AUTOSAR XML (schema 314)
package /ComponentType
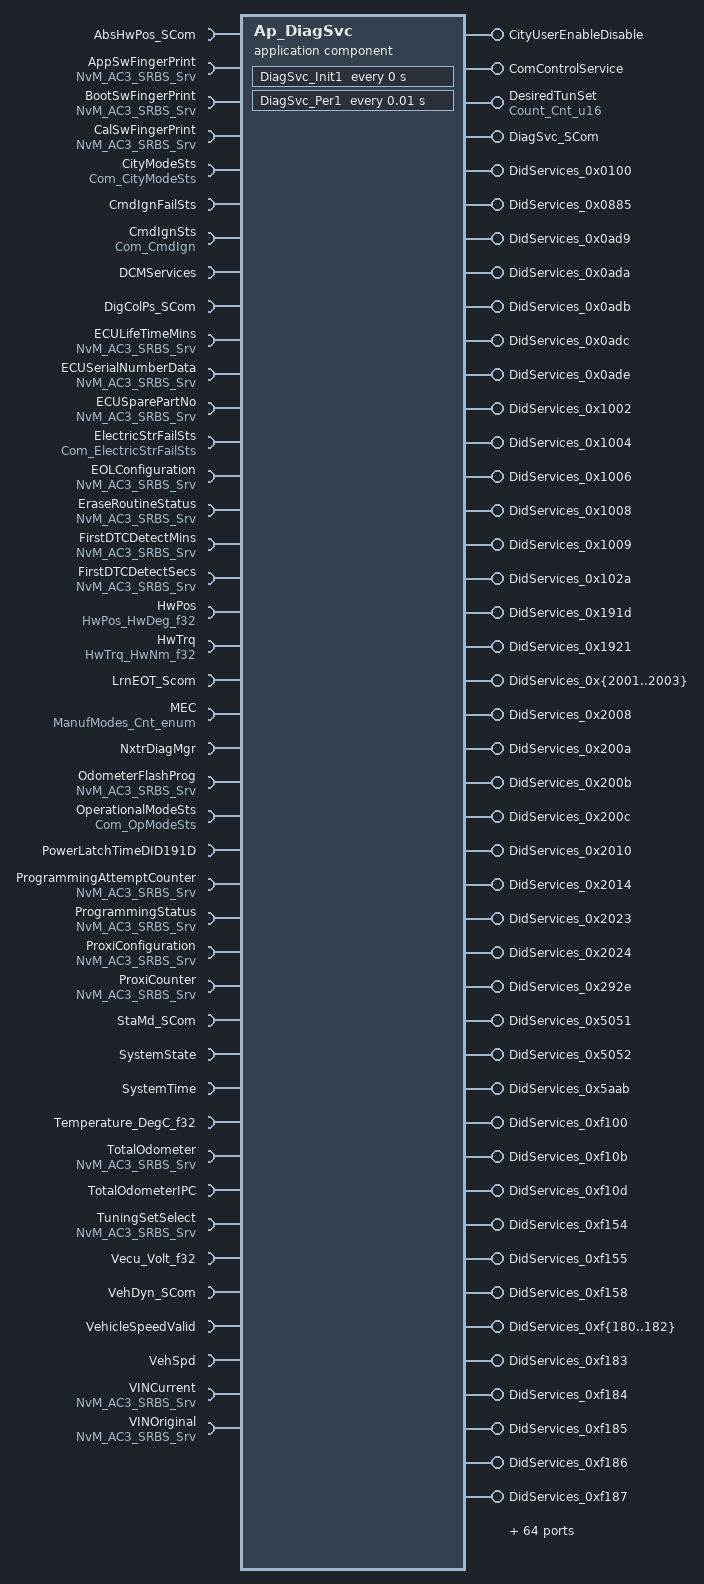
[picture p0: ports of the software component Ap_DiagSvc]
  application software component type Ap_DiagSvc
    118 x provide port:
      CityUserEnableDisable: unqueued-sender-com-spec{data-element=Cnt_enum, can-invalidate=false, init-value=D_CITYUSERENABLEDISABLE_ENUM}, provided-interface=CityUserEnableDisable
      ComControlService: server-com-spec{operation=CheckCondition, queue-length=1}, provided-interface=ComControlService
      DesiredTunSet: unqueued-sender-com-spec{data-element=Cnt_u16, can-invalidate=false, init-value=D_ZERO_CNT_U16}, provided-interface=Count_Cnt_u16
      DiagSvc_SCom: provided-com-specs=[{operation=GetTuningSet, queue-length=1}, {operation=SetTuningSet, queue-length=1}], provided-interface=DiagSvc_SCom
      DidServices_0x0100: provided-interface=DidServices_0x0100
        provided-com-specs:
          operation=ConditionCheckRead, queue-length=1
          operation=ConditionCheckWrite, queue-length=1
          operation=ReadData, queue-length=1
          operation=WriteData, queue-length=1
      DidServices_0x0885: provided-com-specs=[{operation=ConditionCheckRead, queue-length=1}, {operation=ReadData, queue-length=1}], provided-interface=DidServices_0x0885
      DidServices_0x0ad9: provided-com-specs=[{operation=ConditionCheckRead, queue-length=1}, {operation=ReadData, queue-length=1}], provided-interface=DidServices_0x0ad9
      DidServices_0x0ada: provided-com-specs=[{operation=ConditionCheckRead, queue-length=1}, {operation=ReadData, queue-length=1}], provided-interface=DidServices_0x0ada
      DidServices_0x0adb: provided-com-specs=[{operation=ConditionCheckRead, queue-length=1}, {operation=ReadData, queue-length=1}], provided-interface=DidServices_0x0adb
      DidServices_0x0adc: provided-com-specs=[{operation=ConditionCheckRead, queue-length=1}, {operation=ReadData, queue-length=1}], provided-interface=DidServices_0x0adc
      DidServices_0x0ade: provided-com-specs=[{operation=ConditionCheckRead, queue-length=1}, {operation=ReadData, queue-length=1}], provided-interface=DidServices_0x0ade
      DidServices_0x1002: provided-com-specs=[{operation=ConditionCheckRead, queue-length=1}, {operation=ReadData, queue-length=1}], provided-interface=DidServices_0x1002
      DidServices_0x1004: provided-com-specs=[{operation=ConditionCheckRead, queue-length=1}, {operation=ReadData, queue-length=1}], provided-interface=DidServices_0x1004
      DidServices_0x1006: provided-com-specs=[{operation=ConditionCheckRead, queue-length=1}, {operation=ReadData, queue-length=1}], provided-interface=DidServices_0x1006
      DidServices_0x1008: provided-com-specs=[{operation=ConditionCheckRead, queue-length=1}, {operation=ReadData, queue-length=1}], provided-interface=DidServices_0x1008
      DidServices_0x1009: provided-com-specs=[{operation=ConditionCheckRead, queue-length=1}, {operation=ReadData, queue-length=1}], provided-interface=DidServices_0x1009
      DidServices_0x102a: provided-com-specs=[{operation=ConditionCheckRead, queue-length=1}, {operation=ReadData, queue-length=1}], provided-interface=DidServices_0x102a
      DidServices_0x191d: provided-com-specs=[{operation=ConditionCheckRead, queue-length=1}, {operation=ReadData, queue-length=1}], provided-interface=DidServices_0x191d
      DidServices_0x1921: provided-com-specs=[{operation=ConditionCheckRead, queue-length=1}, {operation=ReadData, queue-length=1}], provided-interface=DidServices_0x1921
      DidServices_0x{2001..2003}: provided-com-specs=[{operation=ConditionCheckRead, queue-length=1}, {operation=ReadData, queue-length=1}], provided-interface=DidServices_0x{2001..2003}
      DidServices_0x2008: provided-com-specs=[{operation=ConditionCheckRead, queue-length=1}, {operation=ReadData, queue-length=1}], provided-interface=DidServices_0x2008
      DidServices_0x200a: provided-com-specs=[{operation=ConditionCheckRead, queue-length=1}, {operation=ReadData, queue-length=1}], provided-interface=DidServices_0x200a
      DidServices_0x200b: provided-com-specs=[{operation=ConditionCheckRead, queue-length=1}, {operation=ReadData, queue-length=1}], provided-interface=DidServices_0x200b
      DidServices_0x200c: provided-com-specs=[{operation=ConditionCheckRead, queue-length=1}, {operation=ReadData, queue-length=1}], provided-interface=DidServices_0x200c
      DidServices_0x2010: provided-com-specs=[{operation=ConditionCheckRead, queue-length=1}, {operation=ReadData, queue-length=1}], provided-interface=DidServices_0x2010
      DidServices_0x2014: provided-com-specs=[{operation=ConditionCheckRead, queue-length=1}, {operation=ReadData, queue-length=1}], provided-interface=DidServices_0x2014
      DidServices_0x2023: provided-com-specs=[{operation=ConditionCheckWrite, queue-length=1}, {operation=WriteData, queue-length=1}], provided-interface=DidServices_0x2023
      DidServices_0x2024: provided-com-specs=[{operation=ConditionCheckRead, queue-length=1}, {operation=ReadData, queue-length=1}], provided-interface=DidServices_0x2024
      DidServices_0x292e: provided-com-specs=[{operation=ConditionCheckRead, queue-length=1}, {operation=ReadData, queue-length=1}], provided-interface=DidServices_0x292e
      DidServices_0x5051: provided-interface=DidServices_0x5051
        provided-com-specs:
          operation=ResetToDefault, queue-length=1
          operation=ReturnControlToECU, queue-length=1
          operation=ShortTermAdjustment, queue-length=1
      DidServices_0x5052: provided-com-specs=[{operation=ReturnControlToECU, queue-length=1}, {operation=ShortTermAdjustment, queue-length=1}], provided-interface=DidServices_0x5052
      DidServices_0x5aab: provided-interface=DidServices_0x5aab
        provided-com-specs:
          operation=ResetToDefault, queue-length=1
          operation=ReturnControlToECU, queue-length=1
          operation=ShortTermAdjustment, queue-length=1
      DidServices_0xf100: provided-com-specs=[{operation=ConditionCheckRead, queue-length=1}, {operation=ReadData, queue-length=1}], provided-interface=DidServices_0xf100
      DidServices_0xf10b: provided-interface=DidServices_0xf10b
        provided-com-specs:
          operation=ConditionCheckRead, queue-length=1
          operation=ReadData, queue-length=1
          operation=ReadDataLength, queue-length=1
      DidServices_0xf10d: provided-com-specs=[{operation=ConditionCheckRead, queue-length=1}, {operation=ReadData, queue-length=1}], provided-interface=DidServices_0xf10d
      DidServices_0xf154: provided-com-specs=[{operation=ConditionCheckRead, queue-length=1}, {operation=ReadData, queue-length=1}], provided-interface=DidServices_0xf154
      DidServices_0xf155: provided-com-specs=[{operation=ConditionCheckRead, queue-length=1}, {operation=ReadData, queue-length=1}], provided-interface=DidServices_0xf155
      DidServices_0xf158: provided-com-specs=[{operation=ConditionCheckRead, queue-length=1}, {operation=ReadData, queue-length=1}], provided-interface=DidServices_0xf158
      DidServices_0xf{180..182}: provided-com-specs=[{operation=ConditionCheckRead, queue-length=1}, {operation=ReadData, queue-length=1}], provided-interface=DidServices_0xf{180..182}
      DidServices_0xf183: provided-interface=DidServices_0xf183
        provided-com-specs:
          operation=ConditionCheckRead, queue-length=1
          operation=ConditionCheckWrite, queue-length=1
          operation=ReadData, queue-length=1
          operation=WriteData, queue-length=1
      DidServices_0xf184: provided-interface=DidServices_0xf184
        provided-com-specs:
          operation=ConditionCheckRead, queue-length=1
          operation=ConditionCheckWrite, queue-length=1
          operation=ReadData, queue-length=1
          operation=WriteData, queue-length=1
      DidServices_0xf185: provided-interface=DidServices_0xf185
        provided-com-specs:
          operation=ConditionCheckRead, queue-length=1
          operation=ConditionCheckWrite, queue-length=1
          operation=ReadData, queue-length=1
          operation=WriteData, queue-length=1
      DidServices_0xf186: provided-com-specs=[{operation=ConditionCheckRead, queue-length=1}, {operation=ReadData, queue-length=1}], provided-interface=DidServices_0xf186
      DidServices_0xf187: provided-interface=DidServices_0xf187
        provided-com-specs:
          operation=ConditionCheckRead, queue-length=1
          operation=ConditionCheckWrite, queue-length=1
          operation=ReadData, queue-length=1
          operation=WriteData, queue-length=1
      DidServices_0xf188: provided-com-specs=[{operation=ConditionCheckRead, queue-length=1}, {operation=ReadData, queue-length=1}], provided-interface=DidServices_0xf188
      DidServices_0xf18c: provided-interface=DidServices_0xf18c
        provided-com-specs:
          operation=ConditionCheckRead, queue-length=1
          operation=ConditionCheckWrite, queue-length=1
          operation=ReadData, queue-length=1
          operation=WriteData, queue-length=1
      DidServices_0xf{191..195}: provided-com-specs=[{operation=ConditionCheckRead, queue-length=1}, {operation=ReadData, queue-length=1}], provided-interface=DidServices_0xf{191..195}
      DidServices_0xf1a0: provided-com-specs=[{operation=ConditionCheckRead, queue-length=1}, {operation=ReadData, queue-length=1}], provided-interface=DidServices_0xf1a0
      DidServices_0xf1a3: provided-com-specs=[{operation=ConditionCheckRead, queue-length=1}, {operation=ReadData, queue-length=1}], provided-interface=DidServices_0xf1a3
      DidServices_0xf1a4: provided-com-specs=[{operation=ConditionCheckRead, queue-length=1}, {operation=ReadData, queue-length=1}], provided-interface=DidServices_0xf1a4
      DidServices_0xfd01: provided-com-specs=[{operation=ConditionCheckRead, queue-length=1}, {operation=ReadData, queue-length=1}], provided-interface=DidServices_0xfd01
      DidServices_0xfd02: provided-interface=DidServices_0xfd02
        provided-com-specs:
          operation=ConditionCheckRead, queue-length=1
          operation=ConditionCheckWrite, queue-length=1
          operation=ReadData, queue-length=1
          operation=WriteData, queue-length=1
      DidServices_0xfd03: provided-interface=DidServices_0xfd03
        provided-com-specs:
          operation=ConditionCheckRead, queue-length=1
          operation=ConditionCheckWrite, queue-length=1
          operation=ReadData, queue-length=1
          operation=WriteData, queue-length=1
      DidServices_0xfd07: provided-interface=DidServices_0xfd07
        provided-com-specs:
          operation=ConditionCheckRead, queue-length=1
          operation=ConditionCheckWrite, queue-length=1
          operation=ReadData, queue-length=1
          operation=WriteData, queue-length=1
      DidServices_0xfd0d: provided-com-specs=[{operation=ReturnControlToECU, queue-length=1}, {operation=ShortTermAdjustment, queue-length=1}], provided-interface=DidServices_0xfd0d
      DidServices_0xfd0e: provided-com-specs=[{operation=ConditionCheckRead, queue-length=1}, {operation=ReadData, queue-length=1}], provided-interface=DidServices_0xfd0e
      DidServices_0xfd10: provided-com-specs=[{operation=ConditionCheckRead, queue-length=1}, {operation=ReadData, queue-length=1}], provided-interface=DidServices_0xfd10
      DidServices_0xfd11: provided-com-specs=[{operation=ReturnControlToECU, queue-length=1}, {operation=ShortTermAdjustment, queue-length=1}], provided-interface=DidServices_0xfd11
      DidServices_0xfd12: provided-interface=DidServices_0xfd12
        provided-com-specs:
          operation=ConditionCheckRead, queue-length=1
          operation=ConditionCheckWrite, queue-length=1
          operation=ReadData, queue-length=1
          operation=WriteData, queue-length=1
      DidServices_0xfd13: provided-com-specs=[{operation=ConditionCheckRead, queue-length=1}, {operation=ReadData, queue-length=1}], provided-interface=DidServices_0xfd13
      DidServices_0xfd14: provided-com-specs=[{operation=ConditionCheckRead, queue-length=1}, {operation=ReadData, queue-length=1}], provided-interface=DidServices_0xfd14
      DidServices_0xfd17: provided-com-specs=[{operation=ConditionCheckRead, queue-length=1}, {operation=ReadData, queue-length=1}], provided-interface=DidServices_0xfd17
      DidServices_0xfd19: provided-interface=DidServices_0xfd19
        provided-com-specs:
          operation=ConditionCheckRead, queue-length=1
          operation=ConditionCheckWrite, queue-length=1
          operation=ReadData, queue-length=1
          operation=WriteData, queue-length=1
      DidServices_0xfd1a: provided-com-specs=[{operation=ConditionCheckRead, queue-length=1}, {operation=ReadData, queue-length=1}], provided-interface=DidServices_0xfd1a
      DidServices_0xfd1b: provided-interface=DidServices_0xfd1b
        provided-com-specs:
          operation=ConditionCheckRead, queue-length=1
          operation=ConditionCheckWrite, queue-length=1
          operation=ReadData, queue-length=1
          operation=WriteData, queue-length=1
      DidServices_0xfd1c: provided-com-specs=[{operation=ConditionCheckRead, queue-length=1}, {operation=ReadData, queue-length=1}], provided-interface=DidServices_0xfd1c
      DidServices_0xfd1e: provided-interface=DidServices_0xfd1e
        provided-com-specs:
          operation=ConditionCheckRead, queue-length=1
          operation=ConditionCheckWrite, queue-length=1
          operation=ReadData, queue-length=1
          operation=WriteData, queue-length=1
      DidServices_0xfd20: provided-com-specs=[{operation=ConditionCheckRead, queue-length=1}, {operation=ReadData, queue-length=1}], provided-interface=DidServices_0xfd20
      DidServices_0xfd21: provided-interface=DidServices_0xfd21
        provided-com-specs:
          operation=ConditionCheckRead, queue-length=1
          operation=ConditionCheckWrite, queue-length=1
          operation=ReadData, queue-length=1
          operation=WriteData, queue-length=1
      DidServices_0xfd23: provided-interface=DidServices_0xfd23
        provided-com-specs:
          operation=ConditionCheckRead, queue-length=1
          operation=ConditionCheckWrite, queue-length=1
          operation=ReadData, queue-length=1
          operation=WriteData, queue-length=1
      DidServices_0xfd25: provided-interface=DidServices_0xfd25
        provided-com-specs:
          operation=ConditionCheckRead, queue-length=1
          operation=ConditionCheckWrite, queue-length=1
          operation=ReadData, queue-length=1
          operation=WriteData, queue-length=1
      DidServices_0xfd26: provided-interface=DidServices_0xfd26
        provided-com-specs:
          operation=ConditionCheckRead, queue-length=1
          operation=ConditionCheckWrite, queue-length=1
          operation=ReadData, queue-length=1
          operation=WriteData, queue-length=1
      DidServices_0xfd27: provided-interface=DidServices_0xfd27
        provided-com-specs:
          operation=ConditionCheckRead, queue-length=1
          operation=ConditionCheckWrite, queue-length=1
          operation=ReadData, queue-length=1
          operation=WriteData, queue-length=1
      DidServices_0xfd29: provided-interface=DidServices_0xfd29
        provided-com-specs:
          operation=ConditionCheckRead, queue-length=1
          operation=ConditionCheckWrite, queue-length=1
          operation=ReadData, queue-length=1
          operation=WriteData, queue-length=1
      DidServices_0xfd30: provided-interface=DidServices_0xfd30
        provided-com-specs:
          operation=ConditionCheckRead, queue-length=1
          operation=ConditionCheckWrite, queue-length=1
          operation=ReadData, queue-length=1
          operation=WriteData, queue-length=1
      DidServices_0xfd31: provided-com-specs=[{operation=ConditionCheckRead, queue-length=1}, {operation=ReadData, queue-length=1}], provided-interface=DidServices_0xfd31
      DidServices_0xfda1: provided-interface=DidServices_0xfda1
        provided-com-specs:
          operation=ConditionCheckRead, queue-length=1
          operation=ConditionCheckWrite, queue-length=1
          operation=ReadData, queue-length=1
          operation=WriteData, queue-length=1
      DidServices_0xfda2: provided-interface=DidServices_0xfda2
        provided-com-specs:
          operation=ConditionCheckRead, queue-length=1
          operation=ConditionCheckWrite, queue-length=1
          operation=ReadData, queue-length=1
          operation=WriteData, queue-length=1
      DidServices_0xfda3: provided-interface=DidServices_0xfda3
        provided-com-specs:
          operation=ConditionCheckRead, queue-length=1
          operation=ConditionCheckWrite, queue-length=1
          operation=ReadData, queue-length=1
          operation=WriteData, queue-length=1
      DidServices_0xfdac: provided-interface=DidServices_0xfdac
        provided-com-specs:
          operation=ConditionCheckRead, queue-length=1
          operation=ConditionCheckWrite, queue-length=1
          operation=ReadData, queue-length=1
          operation=WriteData, queue-length=1
      DidServices_0xfdad: provided-com-specs=[{operation=ConditionCheckRead, queue-length=1}, {operation=ReadData, queue-length=1}], provided-interface=DidServices_0xfdad
      DidServices_0xfdae: provided-interface=DidServices_0xfdae
        provided-com-specs:
          operation=ConditionCheckRead, queue-length=1
          operation=ConditionCheckWrite, queue-length=1
          operation=ReadData, queue-length=1
          operation=WriteData, queue-length=1
      DidServices_0xfdaf: provided-com-specs=[{operation=ConditionCheckRead, queue-length=1}, {operation=ReadData, queue-length=1}], provided-interface=DidServices_0xfdaf
      DidServices_0xfdb0: provided-interface=DidServices_0xfdb0
        provided-com-specs:
          operation=ConditionCheckRead, queue-length=1
          operation=ConditionCheckWrite, queue-length=1
          operation=ReadData, queue-length=1
          operation=WriteData, queue-length=1
      DidServices_0xfdb1: provided-interface=DidServices_0xfdb1
        provided-com-specs:
          operation=ConditionCheckRead, queue-length=1
          operation=ConditionCheckWrite, queue-length=1
          operation=ReadData, queue-length=1
          operation=WriteData, queue-length=1
      DidServices_0xfdb2: provided-interface=DidServices_0xfdb2
        provided-com-specs:
          operation=ConditionCheckRead, queue-length=1
          operation=ConditionCheckWrite, queue-length=1
          operation=ReadData, queue-length=1
          operation=WriteData, queue-length=1
      DidServices_0xfdb3: provided-interface=DidServices_0xfdb3
        provided-com-specs:
          operation=ConditionCheckRead, queue-length=1
          operation=ConditionCheckWrite, queue-length=1
          operation=ReadData, queue-length=1
          operation=WriteData, queue-length=1
      DidServices_0xfdb4: provided-interface=DidServices_0xfdb4
        provided-com-specs:
          operation=ConditionCheckRead, queue-length=1
          operation=ConditionCheckWrite, queue-length=1
          operation=ReadData, queue-length=1
          operation=WriteData, queue-length=1
      DidServices_0xfdb5: provided-interface=DidServices_0xfdb5
        provided-com-specs:
          operation=ConditionCheckRead, queue-length=1
          operation=ConditionCheckWrite, queue-length=1
          operation=ReadData, queue-length=1
          operation=WriteData, queue-length=1
      DidServices_0xfdb6: provided-interface=DidServices_0xfdb6
        provided-com-specs:
          operation=ConditionCheckRead, queue-length=1
          operation=ConditionCheckWrite, queue-length=1
          operation=ReadData, queue-length=1
          operation=WriteData, queue-length=1
      DidServices_0xfdb7: provided-interface=DidServices_0xfdb7
        provided-com-specs:
          operation=ConditionCheckRead, queue-length=1
          operation=ConditionCheckWrite, queue-length=1
          operation=ReadData, queue-length=1
          operation=WriteData, queue-length=1
      DisableFailSafeReaction: unqueued-sender-com-spec{data-element=Cnt_lgc, can-invalidate=false, init-value=D_FALSE_CNT_LGC}, provided-interface=DisableFailSafeReaction
      IgnitionPreStart: unqueued-sender-com-spec{data-element=Cnt_lgc, can-invalidate=false, init-value=D_FALSE_CNT_LGC}, provided-interface=BoolStatusFlag_Cnt_lgc
      ProxiValid: unqueued-sender-com-spec{data-element=Cnt_lgc, can-invalidate=false, init-value=D_PROXIVALID}, provided-interface=ProxiValid
      ResetService: server-com-spec{operation=EcuReset, queue-length=1}, provided-interface=ResetService
      RoutineServices_0x0200: provided-com-specs=[{operation=RequestResults, queue-length=1}, {operation=Start, queue-length=1}], provided-interface=RoutineServices_0x0200
      RoutineServices_0xd001: provided-com-specs=[{operation=Start, queue-length=1}, {operation=Stop, queue-length=1}], provided-interface=RoutineServices_0xd001
      RoutineServices_0xd002: server-com-spec{operation=Start, queue-length=1}, provided-interface=RoutineServices_0xd002
      RoutineServices_0xf000: server-com-spec{operation=Start, queue-length=1}, provided-interface=RoutineServices_0xf000
      RoutineServices_0xf001: server-com-spec{operation=Start, queue-length=1}, provided-interface=RoutineServices_0xf001
      RoutineServices_0xf{003..005}: server-com-spec{operation=Start, queue-length=1}, provided-interface=RoutineServices_0xf{003..005}
      RoutineServices_0xf008: server-com-spec{operation=Start, queue-length=1}, provided-interface=RoutineServices_0xf008
      RoutineServices_0xf009: provided-interface=RoutineServices_0xf009
        provided-com-specs:
          operation=RequestResults, queue-length=1
          operation=Start, queue-length=1
          operation=Stop, queue-length=1
      RoutineServices_0xf0ff: server-com-spec{operation=Start, queue-length=1}, provided-interface=RoutineServices_0xf0ff
      RoutineServices_0xfee0: server-com-spec{operation=Start, queue-length=1}, provided-interface=RoutineServices_0xfee0
      SecurityAccess_1: provided-com-specs=[{operation=CompareKey, queue-length=1}, {operation=GetSeed, queue-length=1}], provided-interface=SecurityAccess_1
      SessionControl: provided-interface=SessionControl
        provided-com-specs:
          operation=ChangeIndication, queue-length=1
          operation=ConfirmationRespPending, queue-length=1
          operation=GetSesChgPermission, queue-length=1
      StartStopLogicEnable: unqueued-sender-com-spec{data-element=Cnt_lgc, can-invalidate=false, init-value=D_FALSE_CNT_LGC}, provided-interface=StartStopLogicEnable
    42 x require port:
      AbsHwPos_SCom: required-com-specs=[CustClrTrim, CustSetTrim, NxtClearTrim, NxtSetTrim], required-interface=AbsHwPos_SCom
      AppSwFingerPrint: required-com-specs=[EraseBlock, GetErrorStatus, InvalidateNvBlock, ReadBlock, SetRamBlockStatus, WriteBlock], required-interface=NvM_AC3_SRBS_Srv
      BootSwFingerPrint: required-com-specs=[EraseBlock, GetErrorStatus, InvalidateNvBlock, ReadBlock, SetRamBlockStatus, WriteBlock], required-interface=NvM_AC3_SRBS_Srv
      CalSwFingerPrint: required-com-specs=[EraseBlock, GetErrorStatus, InvalidateNvBlock, ReadBlock, SetRamBlockStatus, WriteBlock], required-interface=NvM_AC3_SRBS_Srv
      CityModeSts: unqueued-receiver-com-spec{data-element=Cnt_lgc, init-value=D_FALSE_CNT_LGC}, required-interface=Com_CityModeSts
      CmdIgnFailSts: unqueued-receiver-com-spec{data-element=Cnt_u8, init-value=C_CmdIgn_FailSts}, required-interface=CmdIgnFailSts
      CmdIgnSts: unqueued-receiver-com-spec{data-element=Cnt_u16, init-value=C_CmdIgnSts}, required-interface=Com_CmdIgn
      DCMServices: required-com-specs=[GetSecurityLevel, GetSesCtrlType], required-interface=DCMServices
      DigColPs_SCom: required-com-specs=[CustClearTrim, CustSetTrim, NxtClrTrim, NxtSetTrim], required-interface=DigColPs_SCom
      ECULifeTimeMins: required-com-specs=[EraseBlock, GetErrorStatus, InvalidateNvBlock, ReadBlock, SetRamBlockStatus, WriteBlock], required-interface=NvM_AC3_SRBS_Srv
      ECUSerialNumberData: required-com-specs=[EraseBlock, GetErrorStatus, InvalidateNvBlock, ReadBlock, SetRamBlockStatus, WriteBlock], required-interface=NvM_AC3_SRBS_Srv
      ECUSparePartNo: required-com-specs=[EraseBlock, GetErrorStatus, InvalidateNvBlock, ReadBlock, SetRamBlockStatus, WriteBlock], required-interface=NvM_AC3_SRBS_Srv
      ElectricStrFailSts: unqueued-receiver-com-spec{data-element=Cnt_lgc, init-value=D_FALSE_CNT_LGC}, required-interface=Com_ElectricStrFailSts
      EOLConfiguration: required-com-specs=[EraseBlock, GetErrorStatus, InvalidateNvBlock, ReadBlock, SetRamBlockStatus, WriteBlock], required-interface=NvM_AC3_SRBS_Srv
      EraseRoutineStatus: required-com-specs=[EraseBlock, GetErrorStatus, InvalidateNvBlock, ReadBlock, SetRamBlockStatus, WriteBlock], required-interface=NvM_AC3_SRBS_Srv
      FirstDTCDetectMins: required-com-specs=[EraseBlock, GetErrorStatus, InvalidateNvBlock, ReadBlock, SetRamBlockStatus, WriteBlock], required-interface=NvM_AC3_SRBS_Srv
      FirstDTCDetectSecs: required-com-specs=[EraseBlock, GetErrorStatus, InvalidateNvBlock, ReadBlock, SetRamBlockStatus, WriteBlock], required-interface=NvM_AC3_SRBS_Srv
      HwPos: unqueued-receiver-com-spec{data-element=HwDeg_f32, init-value=D_ZERO_ULS_F32}, required-interface=HwPos_HwDeg_f32
      HwTrq: unqueued-receiver-com-spec{data-element=HwNm_f32, init-value=D_ZERO_ULS_F32}, required-interface=HwTrq_HwNm_f32
      LrnEOT_Scom: client-com-spec=ResetEOT, required-interface=LrnEOT_Scom
      MEC: unqueued-receiver-com-spec{data-element=Cnt_enum, init-value=D_MANUFMODEINIT_CNT_ENUM}, required-interface=ManufModes_Cnt_enum
      NxtrDiagMgr: required-com-specs=[GetNTCActive, GetNTCFailed, GetNTCStatus, SetNTCStatus], required-interface=NxtrDiagMgr
      OdometerFlashProg: required-com-specs=[EraseBlock, GetErrorStatus, InvalidateNvBlock, ReadBlock, SetRamBlockStatus, WriteBlock], required-interface=NvM_AC3_SRBS_Srv
      OperationalModeSts: unqueued-receiver-com-spec{data-element=Cnt_u16, init-value=C_OperationalModeSts}, required-interface=Com_OpModeSts
      PowerLatchTimeDID191D: unqueued-receiver-com-spec{data-element=Cnt_u16, init-value=D_ZERO_CNT_U16}, required-interface=PowerLatchTimeDID191D
      ProgrammingAttemptCounter: required-com-specs=[EraseBlock, GetErrorStatus, InvalidateNvBlock, ReadBlock, SetRamBlockStatus, WriteBlock], required-interface=NvM_AC3_SRBS_Srv
      ProgrammingStatus: required-com-specs=[EraseBlock, GetErrorStatus, InvalidateNvBlock, ReadBlock, SetRamBlockStatus, WriteBlock], required-interface=NvM_AC3_SRBS_Srv
      ProxiConfiguration: required-com-specs=[EraseBlock, GetErrorStatus, InvalidateNvBlock, ReadBlock, SetRamBlockStatus, WriteBlock], required-interface=NvM_AC3_SRBS_Srv
      ProxiCounter: required-com-specs=[EraseBlock, GetErrorStatus, InvalidateNvBlock, ReadBlock, SetRamBlockStatus, WriteBlock], required-interface=NvM_AC3_SRBS_Srv
      StaMd_SCom: required-com-specs=[EcuReset, FBLTransitionReq], required-interface=StaMd_SCom
      SystemState: required-interface=SystemState
      SystemTime: required-interface=SystemTime
        required-com-specs:
          DtrmnElapsedTime_mS_u16
          DtrmnElapsedTime_mS_u32
          DtrmnElapsedTime_uS_u16
          DtrmnElapsedTime_uS_u32
          GetSystemTime_mS_u32
          GetSystemTime_uS_u32
      Temperature_DegC_f32: unqueued-receiver-com-spec{data-element=DegC_f32, init-value=D_ZERO_ULS_F32}, required-interface=Temperature_DegC_f32
      TotalOdometer: required-com-specs=[EraseBlock, GetErrorStatus, InvalidateNvBlock, ReadBlock, SetRamBlockStatus, WriteBlock], required-interface=NvM_AC3_SRBS_Srv
      TotalOdometerIPC: unqueued-receiver-com-spec{data-element=Cnt_u32, init-value=D_ZERO_CNT_U32}, required-interface=TotalOdometerIPC
      TuningSetSelect: required-com-specs=[EraseBlock, GetErrorStatus, InvalidateNvBlock, ReadBlock, SetRamBlockStatus, WriteBlock], required-interface=NvM_AC3_SRBS_Srv
      Vecu_Volt_f32: unqueued-receiver-com-spec{data-element=Volt_f32, init-value=D_VECUMIN_VOLTS_F32}, required-interface=Vecu_Volt_f32
      VehDyn_SCom: required-com-specs=[ForceCenter, ResetCenter], required-interface=VehDyn_SCom
      VehicleSpeedValid: unqueued-receiver-com-spec{data-element=Cnt_lgc, init-value=D_FALSE_CNT_LGC}, required-interface=VehicleSpeedValid
      VehSpd: unqueued-receiver-com-spec{data-element=Kph_f32, init-value=D_ZERO_ULS_F32}, required-interface=VehSpd
      VINCurrent: required-com-specs=[EraseBlock, GetErrorStatus, InvalidateNvBlock, ReadBlock, SetRamBlockStatus, WriteBlock], required-interface=NvM_AC3_SRBS_Srv
      VINOriginal: required-com-specs=[EraseBlock, GetErrorStatus, InvalidateNvBlock, ReadBlock, SetRamBlockStatus, WriteBlock], required-interface=NvM_AC3_SRBS_Srv
  internal behavior Ap_DiagSvc_InternalBehavior: component=Ap_DiagSvc
    operation invoked event OIT_ComControlService_CheckCondition_ComControlService_CheckCondition: start-on-event=ComControlService_CheckCondition, operation=ComControlService.CheckCondition
    timing event DiagSvc_Init1_InitEvent: start-on-event=DiagSvc_Init1, period=0
    timing event TMT_DiagSvc_Per1: start-on-event=DiagSvc_Per1, period=0.01
    operation invoked event OIT_DiagSvc_SCom_GetTuningSet_DiagSvc_SCom_GetTuningSet: start-on-event=DiagSvc_SCom_GetTuningSet, operation=DiagSvc_SCom.GetTuningSet
    operation invoked event OIT_DiagSvc_SCom_SetTuningSet_DiagSvc_SCom_SetTuningSet: start-on-event=DiagSvc_SCom_SetTuningSet, operation=DiagSvc_SCom.SetTuningSet
    mode switch event MST_DiagSvc_Trns1_0: start-on-event=DiagSvc_Trns1, activation=ENTRY, mode=SystemState.Mode.OFF
    281 x operation invoked event:
      OIT_DidServices_0x0100_ReadData_DidServices_0x0100_ReadData: start-on-event=DidServices_0x0100_ReadData, operation=DidServices_0x0100.ReadData
      OIT_DidServices_0x0100_WriteData_DidServices_0x0100_WriteData: start-on-event=DidServices_0x0100_WriteData, operation=DidServices_0x0100.WriteData
      OIT_DidServices_0x0885_ReadData_DidServices_0x0885_ReadData: start-on-event=DidServices_0x0885_ReadData, operation=DidServices_0x0885.ReadData
      OIT_DidServices_0x0ad9_ReadData_DidServices_0x0ad9_ReadData: start-on-event=DidServices_0x0ad9_ReadData, operation=DidServices_0x0ad9.ReadData
      OIT_DidServices_0x0ada_ReadData_DidServices_0x0ada_ReadData: start-on-event=DidServices_0x0ada_ReadData, operation=DidServices_0x0ada.ReadData
      OIT_DidServices_0x0adb_ReadData_DidServices_0x0adb_ReadData: start-on-event=DidServices_0x0adb_ReadData, operation=DidServices_0x0adb.ReadData
      OIT_DidServices_0x0adc_ReadData_DidServices_0x0adc_ReadData: start-on-event=DidServices_0x0adc_ReadData, operation=DidServices_0x0adc.ReadData
      OIT_DidServices_0x0ade_ReadData_DidServices_0x0ade_ReadData: start-on-event=DidServices_0x0ade_ReadData, operation=DidServices_0x0ade.ReadData
      OIT_DidServices_0x1002_ReadData_DidServices_0x1002_ReadData: start-on-event=DidServices_0x1002_ReadData, operation=DidServices_0x1002.ReadData
      OIT_DidServices_0x1004_ReadData_DidServices_0x1004_ReadData: start-on-event=DidServices_0x1004_ReadData, operation=DidServices_0x1004.ReadData
      OIT_DidServices_0x1006_ReadData_DidServices_0x1006_ReadData: start-on-event=DidServices_0x1006_ReadData, operation=DidServices_0x1006.ReadData
      OIT_DidServices_0x1008_ReadData_DidServices_0x1008_ReadData: start-on-event=DidServices_0x1008_ReadData, operation=DidServices_0x1008.ReadData
      OIT_DidServices_0x1009_ReadData_DidServices_0x1009_ReadData: start-on-event=DidServices_0x1009_ReadData, operation=DidServices_0x1009.ReadData
      OIT_DidServices_0x102a_ReadData_DidServices_0x102a_ReadData: start-on-event=DidServices_0x102a_ReadData, operation=DidServices_0x102a.ReadData
      OIT_DidServices_0x191d_ReadData_DidServices_0x191d_ReadData: start-on-event=DidServices_0x191d_ReadData, operation=DidServices_0x191d.ReadData
      OIT_DidServices_0x1921_ReadData_DidServices_0x1921_ReadData: start-on-event=DidServices_0x1921_ReadData, operation=DidServices_0x1921.ReadData
      OIT_DidServices_0x{2001..2003}_ReadData_DidServices_0x{2001..2003}_ReadData: start-on-event=DidServices_0x{2001..2003}_ReadData, operation=DidServices_0x{2001..2003}.ReadData
      OIT_DidServices_0x2008_ReadData_DidServices_0x2008_ReadData: start-on-event=DidServices_0x2008_ReadData, operation=DidServices_0x2008.ReadData
      OIT_DidServices_0x200a_ReadData_DidServices_0x200a_ReadData: start-on-event=DidServices_0x200a_ReadData, operation=DidServices_0x200a.ReadData
      OIT_DidServices_0x200b_ReadData_DidServices_0x200b_ReadData: start-on-event=DidServices_0x200b_ReadData, operation=DidServices_0x200b.ReadData
      OIT_DidServices_0x200c_ReadData_DidServices_0x200c_ReadData: start-on-event=DidServices_0x200c_ReadData, operation=DidServices_0x200c.ReadData
      OIT_DidServices_0x2010_ReadData_DidServices_0x2010_ReadData: start-on-event=DidServices_0x2010_ReadData, operation=DidServices_0x2010.ReadData
      OIT_DidServices_0x2014_ReadData_DidServices_0x2014_ReadData: start-on-event=DidServices_0x2014_ReadData, operation=DidServices_0x2014.ReadData
      OIT_DidServices_0x2023_WriteData_DidServices_0x2023_WriteData: start-on-event=DidServices_0x2023_WriteData, operation=DidServices_0x2023.WriteData
      OIT_DidServices_0x2024_ReadData_DidServices_0x2024_ReadData: start-on-event=DidServices_0x2024_ReadData, operation=DidServices_0x2024.ReadData
      OIT_DidServices_0x292e_ReadData_DidServices_0x292e_ReadData: start-on-event=DidServices_0x292e_ReadData, operation=DidServices_0x292e.ReadData
      OIT_DidServices_0x5051_ResetToDefault_DidServices_0x5051_ResetToDefault: start-on-event=DidServices_0x5051_ResetToDefault, operation=DidServices_0x5051.ResetToDefault
      OIT_DidServices_0x5051_ReturnControlToECU_DidServices_0x5051_ReturnControlToECU: start-on-event=DidServices_0x5051_ReturnControlToECU, operation=DidServices_0x5051.ReturnControlToECU
      OIT_DidServices_0x5051_ShortTermAdjustment_DidServices_0x5051_ShortTermAdjustment: start-on-event=DidServices_0x5051_ShortTermAdjustment, operation=DidServices_0x5051.ShortTermAdjustment
      OIT_DidServices_0x5052_ReturnControlToECU_DidServices_0x5052_ReturnControlToECU: start-on-event=DidServices_0x5052_ReturnControlToECU, operation=DidServices_0x5052.ReturnControlToECU
      OIT_DidServices_0x5052_ShortTermAdjustment_DidServices_0x5052_ShortTermAdjustment: start-on-event=DidServices_0x5052_ShortTermAdjustment, operation=DidServices_0x5052.ShortTermAdjustment
      OIT_DidServices_0x5aab_ResetToDefault_DidServices_0x5aab_ResetToDefault: start-on-event=DidServices_0x5aab_ResetToDefault, operation=DidServices_0x5aab.ResetToDefault
      OIT_DidServices_0x5aab_ReturnControlToECU_DidServices_0x5aab_ReturnControlToECU: start-on-event=DidServices_0x5aab_ReturnControlToECU, operation=DidServices_0x5aab.ReturnControlToECU
      OIT_DidServices_0x5aab_ShortTermAdjustment_DidServices_0x5aab_ShortTermAdjustment: start-on-event=DidServices_0x5aab_ShortTermAdjustment, operation=DidServices_0x5aab.ShortTermAdjustment
      OIT_DidServices_0xf100_ReadData_DidServices_0xf100_ReadData: start-on-event=DidServices_0xf100_ReadData, operation=DidServices_0xf100.ReadData
      OIT_DidServices_0xf10b_ReadData_DidServices_0xf10b_ReadData: start-on-event=DidServices_0xf10b_ReadData, operation=DidServices_0xf10b.ReadData
      OIT_DidServices_0xf10b_ReadDataLength_DidServices_0xf10b_ReadDataLength: start-on-event=DidServices_0xf10b_ReadDataLength, operation=DidServices_0xf10b.ReadDataLength
      OIT_DidServices_0xf10d_ReadData_DidServices_0xf10d_ReadData: start-on-event=DidServices_0xf10d_ReadData, operation=DidServices_0xf10d.ReadData
      OIT_DidServices_0xf154_ReadData_DidServices_0xf154_ReadData: start-on-event=DidServices_0xf154_ReadData, operation=DidServices_0xf154.ReadData
      OIT_DidServices_0xf155_ReadData_DidServices_0xf155_ReadData: start-on-event=DidServices_0xf155_ReadData, operation=DidServices_0xf155.ReadData
      OIT_DidServices_0xf158_ReadData_DidServices_0xf158_ReadData: start-on-event=DidServices_0xf158_ReadData, operation=DidServices_0xf158.ReadData
      OIT_DidServices_0xf{180..183}_ReadData_DidServices_0xf{180..183}_ReadData: start-on-event=DidServices_0xf{180..183}_ReadData, operation=DidServices_0xf{180..183}.ReadData
      OIT_DidServices_0xf183_WriteData_DidServices_0xf183_WriteData: start-on-event=DidServices_0xf183_WriteData, operation=DidServices_0xf183.WriteData
      OIT_DidServices_0xf184_ReadData_DidServices_0xf184_ReadData: start-on-event=DidServices_0xf184_ReadData, operation=DidServices_0xf184.ReadData
      OIT_DidServices_0xf184_WriteData_DidServices_0xf184_WriteData: start-on-event=DidServices_0xf184_WriteData, operation=DidServices_0xf184.WriteData
      OIT_DidServices_0xf185_ReadData_DidServices_0xf185_ReadData: start-on-event=DidServices_0xf185_ReadData, operation=DidServices_0xf185.ReadData
      OIT_DidServices_0xf185_WriteData_DidServices_0xf185_WriteData: start-on-event=DidServices_0xf185_WriteData, operation=DidServices_0xf185.WriteData
      OIT_DidServices_0xf186_ReadData_DidServices_0xf186_ReadData: start-on-event=DidServices_0xf186_ReadData, operation=DidServices_0xf186.ReadData
      OIT_DidServices_0xf187_ReadData_DidServices_0xf187_ReadData: start-on-event=DidServices_0xf187_ReadData, operation=DidServices_0xf187.ReadData
      OIT_DidServices_0xf187_WriteData_DidServices_0xf187_WriteData: start-on-event=DidServices_0xf187_WriteData, operation=DidServices_0xf187.WriteData
      OIT_DidServices_0xf188_ReadData_DidServices_0xf188_ReadData: start-on-event=DidServices_0xf188_ReadData, operation=DidServices_0xf188.ReadData
      OIT_DidServices_0xf18c_ReadData_DidServices_0xf18c_ReadData: start-on-event=DidServices_0xf18c_ReadData, operation=DidServices_0xf18c.ReadData
      OIT_DidServices_0xf18c_WriteData_DidServices_0xf18c_WriteData: start-on-event=DidServices_0xf18c_WriteData, operation=DidServices_0xf18c.WriteData
      OIT_DidServices_0xf{191..195}_ReadData_DidServices_0xf{191..195}_ReadData: start-on-event=DidServices_0xf{191..195}_ReadData, operation=DidServices_0xf{191..195}.ReadData
      OIT_DidServices_0xf1a0_ReadData_DidServices_0xf1a0_ReadData: start-on-event=DidServices_0xf1a0_ReadData, operation=DidServices_0xf1a0.ReadData
      OIT_DidServices_0xf1a3_ReadData_DidServices_0xf1a3_ReadData: start-on-event=DidServices_0xf1a3_ReadData, operation=DidServices_0xf1a3.ReadData
      OIT_DidServices_0xf1a4_ReadData_DidServices_0xf1a4_ReadData: start-on-event=DidServices_0xf1a4_ReadData, operation=DidServices_0xf1a4.ReadData
      OIT_DidServices_0xfd01_ReadData_DidServices_0xfd01_ReadData: start-on-event=DidServices_0xfd01_ReadData, operation=DidServices_0xfd01.ReadData
      OIT_DidServices_0xfd02_ReadData_DidServices_0xfd02_ReadData: start-on-event=DidServices_0xfd02_ReadData, operation=DidServices_0xfd02.ReadData
      OIT_DidServices_0xfd02_WriteData_DidServices_0xfd02_WriteData: start-on-event=DidServices_0xfd02_WriteData, operation=DidServices_0xfd02.WriteData
      OIT_DidServices_0xfd03_ReadData_DidServices_0xfd03_ReadData: start-on-event=DidServices_0xfd03_ReadData, operation=DidServices_0xfd03.ReadData
      OIT_DidServices_0xfd03_WriteData_DidServices_0xfd03_WriteData: start-on-event=DidServices_0xfd03_WriteData, operation=DidServices_0xfd03.WriteData
      OIT_DidServices_0xfd07_ReadData_DidServices_0xfd07_ReadData: start-on-event=DidServices_0xfd07_ReadData, operation=DidServices_0xfd07.ReadData
      OIT_DidServices_0xfd07_WriteData_DidServices_0xfd07_WriteData: start-on-event=DidServices_0xfd07_WriteData, operation=DidServices_0xfd07.WriteData
      OIT_DidServices_0xfd0d_ReturnControlToECU_DidServices_0xfd0d_ReturnControlToECU: start-on-event=DidServices_0xfd0d_ReturnControlToECU, operation=DidServices_0xfd0d.ReturnControlToECU
      OIT_DidServices_0xfd0d_ShortTermAdjustment_DidServices_0xfd0d_ShortTermAdjustment: start-on-event=DidServices_0xfd0d_ShortTermAdjustment, operation=DidServices_0xfd0d.ShortTermAdjustment
      OIT_DidServices_0xfd0e_ReadData_DidServices_0xfd0e_ReadData: start-on-event=DidServices_0xfd0e_ReadData, operation=DidServices_0xfd0e.ReadData
      OIT_DidServices_0xfd10_ReadData_DidServices_0xfd10_ReadData: start-on-event=DidServices_0xfd10_ReadData, operation=DidServices_0xfd10.ReadData
      OIT_DidServices_0xfd11_ReturnControlToECU_DidServices_0xfd11_ReturnControlToECU: start-on-event=DidServices_0xfd11_ReturnControlToECU, operation=DidServices_0xfd11.ReturnControlToECU
      OIT_DidServices_0xfd11_ShortTermAdjustment_DidServices_0xfd11_ShortTermAdjustment: start-on-event=DidServices_0xfd11_ShortTermAdjustment, operation=DidServices_0xfd11.ShortTermAdjustment
      OIT_DidServices_0xfd12_ReadData_DidServices_0xfd12_ReadData: start-on-event=DidServices_0xfd12_ReadData, operation=DidServices_0xfd12.ReadData
      OIT_DidServices_0xfd12_WriteData_DidServices_0xfd12_WriteData: start-on-event=DidServices_0xfd12_WriteData, operation=DidServices_0xfd12.WriteData
      OIT_DidServices_0xfd13_ReadData_DidServices_0xfd13_ReadData: start-on-event=DidServices_0xfd13_ReadData, operation=DidServices_0xfd13.ReadData
      OIT_DidServices_0xfd14_ReadData_DidServices_0xfd14_ReadData: start-on-event=DidServices_0xfd14_ReadData, operation=DidServices_0xfd14.ReadData
      OIT_DidServices_0xfd17_ReadData_DidServices_0xfd17_ReadData: start-on-event=DidServices_0xfd17_ReadData, operation=DidServices_0xfd17.ReadData
      OIT_DidServices_0xfd19_ReadData_DidServices_0xfd19_ReadData: start-on-event=DidServices_0xfd19_ReadData, operation=DidServices_0xfd19.ReadData
      OIT_DidServices_0xfd19_WriteData_DidServices_0xfd19_WriteData: start-on-event=DidServices_0xfd19_WriteData, operation=DidServices_0xfd19.WriteData
      OIT_DidServices_0xfd1a_ReadData_DidServices_0xfd1a_ReadData: start-on-event=DidServices_0xfd1a_ReadData, operation=DidServices_0xfd1a.ReadData
      OIT_DidServices_0xfd1b_ReadData_DidServices_0xfd1b_ReadData: start-on-event=DidServices_0xfd1b_ReadData, operation=DidServices_0xfd1b.ReadData
      OIT_DidServices_0xfd1b_WriteData_DidServices_0xfd1b_WriteData: start-on-event=DidServices_0xfd1b_WriteData, operation=DidServices_0xfd1b.WriteData
      OIT_DidServices_0xfd1c_ReadData_DidServices_0xfd1c_ReadData: start-on-event=DidServices_0xfd1c_ReadData, operation=DidServices_0xfd1c.ReadData
      OIT_DidServices_0xfd1e_ReadData_DidServices_0xfd1e_ReadData: start-on-event=DidServices_0xfd1e_ReadData, operation=DidServices_0xfd1e.ReadData
      OIT_DidServices_0xfd1e_WriteData_DidServices_0xfd1e_WriteData: start-on-event=DidServices_0xfd1e_WriteData, operation=DidServices_0xfd1e.WriteData
      OIT_DidServices_0xfd20_ReadData_DidServices_0xfd20_ReadData: start-on-event=DidServices_0xfd20_ReadData, operation=DidServices_0xfd20.ReadData
      OIT_DidServices_0xfd21_ReadData_DidServices_0xfd21_ReadData: start-on-event=DidServices_0xfd21_ReadData, operation=DidServices_0xfd21.ReadData
      OIT_DidServices_0xfd21_WriteData_DidServices_0xfd21_WriteData: start-on-event=DidServices_0xfd21_WriteData, operation=DidServices_0xfd21.WriteData
      OIT_DidServices_0xfd23_ReadData_DidServices_0xfd23_ReadData: start-on-event=DidServices_0xfd23_ReadData, operation=DidServices_0xfd23.ReadData
      OIT_DidServices_0xfd23_WriteData_DidServices_0xfd23_WriteData: start-on-event=DidServices_0xfd23_WriteData, operation=DidServices_0xfd23.WriteData
      OIT_DidServices_0xfd25_ReadData_DidServices_0xfd25_ReadData: start-on-event=DidServices_0xfd25_ReadData, operation=DidServices_0xfd25.ReadData
      OIT_DidServices_0xfd25_WriteData_DidServices_0xfd25_WriteData: start-on-event=DidServices_0xfd25_WriteData, operation=DidServices_0xfd25.WriteData
      OIT_DidServices_0xfd26_ReadData_DidServices_0xfd26_ReadData: start-on-event=DidServices_0xfd26_ReadData, operation=DidServices_0xfd26.ReadData
      OIT_DidServices_0xfd26_WriteData_DidServices_0xfd26_WriteData: start-on-event=DidServices_0xfd26_WriteData, operation=DidServices_0xfd26.WriteData
      OIT_DidServices_0xfd27_ReadData_DidServices_0xfd27_ReadData: start-on-event=DidServices_0xfd27_ReadData, operation=DidServices_0xfd27.ReadData
      OIT_DidServices_0xfd27_WriteData_DidServices_0xfd27_WriteData: start-on-event=DidServices_0xfd27_WriteData, operation=DidServices_0xfd27.WriteData
      OIT_DidServices_0xfd29_ReadData_DidServices_0xfd29_ReadData: start-on-event=DidServices_0xfd29_ReadData, operation=DidServices_0xfd29.ReadData
      OIT_DidServices_0xfd29_WriteData_DidServices_0xfd29_WriteData: start-on-event=DidServices_0xfd29_WriteData, operation=DidServices_0xfd29.WriteData
      OIT_DidServices_0xfd30_ReadData_DidServices_0xfd30_ReadData: start-on-event=DidServices_0xfd30_ReadData, operation=DidServices_0xfd30.ReadData
      OIT_DidServices_0xfd30_WriteData_DidServices_0xfd30_WriteData: start-on-event=DidServices_0xfd30_WriteData, operation=DidServices_0xfd30.WriteData
      OIT_DidServices_0xfd31_ReadData_DidServices_0xfd31_ReadData: start-on-event=DidServices_0xfd31_ReadData, operation=DidServices_0xfd31.ReadData
      OIT_DidServices_0xfda1_ReadData_DidServices_0xfda1_ReadData: start-on-event=DidServices_0xfda1_ReadData, operation=DidServices_0xfda1.ReadData
      OIT_DidServices_0xfda1_WriteData_DidServices_0xfda1_WriteData: start-on-event=DidServices_0xfda1_WriteData, operation=DidServices_0xfda1.WriteData
      OIT_DidServices_0xfda2_ReadData_DidServices_0xfda2_ReadData: start-on-event=DidServices_0xfda2_ReadData, operation=DidServices_0xfda2.ReadData
      OIT_DidServices_0xfda2_WriteData_DidServices_0xfda2_WriteData: start-on-event=DidServices_0xfda2_WriteData, operation=DidServices_0xfda2.WriteData
      OIT_DidServices_0xfda3_ReadData_DidServices_0xfda3_ReadData: start-on-event=DidServices_0xfda3_ReadData, operation=DidServices_0xfda3.ReadData
      OIT_DidServices_0xfda3_WriteData_DidServices_0xfda3_WriteData: start-on-event=DidServices_0xfda3_WriteData, operation=DidServices_0xfda3.WriteData
      OIT_DidServices_0xfdac_ReadData_DidServices_0xfdac_ReadData: start-on-event=DidServices_0xfdac_ReadData, operation=DidServices_0xfdac.ReadData
      OIT_DidServices_0xfdac_WriteData_DidServices_0xfdac_WriteData: start-on-event=DidServices_0xfdac_WriteData, operation=DidServices_0xfdac.WriteData
      OIT_DidServices_0xfdad_ReadData_DidServices_0xfdad_ReadData: start-on-event=DidServices_0xfdad_ReadData, operation=DidServices_0xfdad.ReadData
      OIT_DidServices_0xfdae_ReadData_DidServices_0xfdae_ReadData: start-on-event=DidServices_0xfdae_ReadData, operation=DidServices_0xfdae.ReadData
      OIT_DidServices_0xfdae_WriteData_DidServices_0xfdae_WriteData: start-on-event=DidServices_0xfdae_WriteData, operation=DidServices_0xfdae.WriteData
      OIT_DidServices_0xfdaf_ReadData_DidServices_0xfdaf_ReadData: start-on-event=DidServices_0xfdaf_ReadData, operation=DidServices_0xfdaf.ReadData
      OIT_DidServices_0xfdb0_ReadData_DidServices_0xfdb0_ReadData: start-on-event=DidServices_0xfdb0_ReadData, operation=DidServices_0xfdb0.ReadData
      OIT_DidServices_0xfdb0_WriteData_DidServices_0xfdb0_WriteData: start-on-event=DidServices_0xfdb0_WriteData, operation=DidServices_0xfdb0.WriteData
      OIT_DidServices_0xfdb1_ReadData_DidServices_0xfdb1_ReadData: start-on-event=DidServices_0xfdb1_ReadData, operation=DidServices_0xfdb1.ReadData
      OIT_DidServices_0xfdb1_WriteData_DidServices_0xfdb1_WriteData: start-on-event=DidServices_0xfdb1_WriteData, operation=DidServices_0xfdb1.WriteData
      OIT_DidServices_0xfdb2_ReadData_DidServices_0xfdb2_ReadData: start-on-event=DidServices_0xfdb2_ReadData, operation=DidServices_0xfdb2.ReadData
      OIT_DidServices_0xfdb2_WriteData_DidServices_0xfdb2_WriteData: start-on-event=DidServices_0xfdb2_WriteData, operation=DidServices_0xfdb2.WriteData
      OIT_DidServices_0xfdb3_ReadData_DidServices_0xfdb3_ReadData: start-on-event=DidServices_0xfdb3_ReadData, operation=DidServices_0xfdb3.ReadData
      OIT_DidServices_0xfdb3_WriteData_DidServices_0xfdb3_WriteData: start-on-event=DidServices_0xfdb3_WriteData, operation=DidServices_0xfdb3.WriteData
      OIT_DidServices_0xfdb4_ReadData_DidServices_0xfdb4_ReadData: start-on-event=DidServices_0xfdb4_ReadData, operation=DidServices_0xfdb4.ReadData
      OIT_DidServices_0xfdb4_WriteData_DidServices_0xfdb4_WriteData: start-on-event=DidServices_0xfdb4_WriteData, operation=DidServices_0xfdb4.WriteData
      OIT_DidServices_0xfdb5_ReadData_DidServices_0xfdb5_ReadData: start-on-event=DidServices_0xfdb5_ReadData, operation=DidServices_0xfdb5.ReadData
      OIT_DidServices_0xfdb5_WriteData_DidServices_0xfdb5_WriteData: start-on-event=DidServices_0xfdb5_WriteData, operation=DidServices_0xfdb5.WriteData
      OIT_DidServices_0xfdb6_ReadData_DidServices_0xfdb6_ReadData: start-on-event=DidServices_0xfdb6_ReadData, operation=DidServices_0xfdb6.ReadData
      OIT_DidServices_0xfdb6_WriteData_DidServices_0xfdb6_WriteData: start-on-event=DidServices_0xfdb6_WriteData, operation=DidServices_0xfdb6.WriteData
      OIT_DidServices_0xfdb7_ReadData_DidServices_0xfdb7_ReadData: start-on-event=DidServices_0xfdb7_ReadData, operation=DidServices_0xfdb7.ReadData
      OIT_DidServices_0xfdb7_WriteData_DidServices_0xfdb7_WriteData: start-on-event=DidServices_0xfdb7_WriteData, operation=DidServices_0xfdb7.WriteData
      OIT_DidServices_ConditionCheckRead_DidServices_0x0100_ConditionCheckRead: start-on-event=DidServices_ConditionCheckRead, operation=DidServices_0x0100.ConditionCheckRead
      OIT_DidServices_ConditionCheckRead_DidServices_0x0885_ConditionCheckRead: start-on-event=DidServices_ConditionCheckRead, operation=DidServices_0x0885.ConditionCheckRead
      OIT_DidServices_ConditionCheckRead_DidServices_0x0ad9_ConditionCheckRead: start-on-event=DidServices_ConditionCheckRead, operation=DidServices_0x0ad9.ConditionCheckRead
      OIT_DidServices_ConditionCheckRead_DidServices_0x0ada_ConditionCheckRead: start-on-event=DidServices_ConditionCheckRead, operation=DidServices_0x0ada.ConditionCheckRead
      OIT_DidServices_ConditionCheckRead_DidServices_0x0adb_ConditionCheckRead: start-on-event=DidServices_ConditionCheckRead, operation=DidServices_0x0adb.ConditionCheckRead
      OIT_DidServices_ConditionCheckRead_DidServices_0x0adc_ConditionCheckRead: start-on-event=DidServices_ConditionCheckRead, operation=DidServices_0x0adc.ConditionCheckRead
      OIT_DidServices_ConditionCheckRead_DidServices_0x0ade_ConditionCheckRead: start-on-event=DidServices_ConditionCheckRead, operation=DidServices_0x0ade.ConditionCheckRead
      OIT_DidServices_ConditionCheckRead_DidServices_0x1002_ConditionCheckRead: start-on-event=DidServices_ConditionCheckRead, operation=DidServices_0x1002.ConditionCheckRead
      OIT_DidServices_ConditionCheckRead_DidServices_0x1004_ConditionCheckRead: start-on-event=DidServices_ConditionCheckRead, operation=DidServices_0x1004.ConditionCheckRead
      OIT_DidServices_ConditionCheckRead_DidServices_0x1006_ConditionCheckRead: start-on-event=DidServices_ConditionCheckRead, operation=DidServices_0x1006.ConditionCheckRead
      OIT_DidServices_ConditionCheckRead_DidServices_0x1008_ConditionCheckRead: start-on-event=DidServices_ConditionCheckRead, operation=DidServices_0x1008.ConditionCheckRead
      OIT_DidServices_ConditionCheckRead_DidServices_0x1009_ConditionCheckRead: start-on-event=DidServices_ConditionCheckRead, operation=DidServices_0x1009.ConditionCheckRead
      OIT_DidServices_ConditionCheckRead_DidServices_0x102a_ConditionCheckRead: start-on-event=DidServices_ConditionCheckRead, operation=DidServices_0x102a.ConditionCheckRead
      OIT_DidServices_ConditionCheckRead_DidServices_0x191d_ConditionCheckRead: start-on-event=DidServices_ConditionCheckRead, operation=DidServices_0x191d.ConditionCheckRead
      OIT_DidServices_ConditionCheckRead_DidServices_0x1921_ConditionCheckRead: start-on-event=DidServices_ConditionCheckRead, operation=DidServices_0x1921.ConditionCheckRead
      OIT_DidServices_ConditionCheckRead_DidServices_0x{2001..2003}_ConditionCheckRead: start-on-event=DidServices_ConditionCheckRead, operation=DidServices_0x{2001..2003}.ConditionCheckRead
      OIT_DidServices_ConditionCheckRead_DidServices_0x2008_ConditionCheckRead: start-on-event=DidServices_ConditionCheckRead, operation=DidServices_0x2008.ConditionCheckRead
      OIT_DidServices_ConditionCheckRead_DidServices_0x200a_ConditionCheckRead: start-on-event=DidServices_ConditionCheckRead, operation=DidServices_0x200a.ConditionCheckRead
      OIT_DidServices_ConditionCheckRead_DidServices_0x200b_ConditionCheckRead: start-on-event=DidServices_ConditionCheckRead, operation=DidServices_0x200b.ConditionCheckRead
      OIT_DidServices_ConditionCheckRead_DidServices_0x200c_ConditionCheckRead: start-on-event=DidServices_ConditionCheckRead, operation=DidServices_0x200c.ConditionCheckRead
      OIT_DidServices_ConditionCheckRead_DidServices_0x2010_ConditionCheckRead: start-on-event=DidServices_ConditionCheckRead, operation=DidServices_0x2010.ConditionCheckRead
      OIT_DidServices_ConditionCheckRead_DidServices_0x2014_ConditionCheckRead: start-on-event=DidServices_ConditionCheckRead, operation=DidServices_0x2014.ConditionCheckRead
      OIT_DidServices_ConditionCheckRead_DidServices_0x2024_ConditionCheckRead: start-on-event=DidServices_ConditionCheckRead, operation=DidServices_0x2024.ConditionCheckRead
      OIT_DidServices_ConditionCheckRead_DidServices_0x292e_ConditionCheckRead: start-on-event=DidServices_ConditionCheckRead, operation=DidServices_0x292e.ConditionCheckRead
      OIT_DidServices_ConditionCheckRead_DidServices_0xf100_ConditionCheckRead: start-on-event=DidServices_ConditionCheckRead, operation=DidServices_0xf100.ConditionCheckRead
      OIT_DidServices_ConditionCheckRead_DidServices_0xf10b_ConditionCheckRead: start-on-event=DidServices_ConditionCheckRead, operation=DidServices_0xf10b.ConditionCheckRead
      OIT_DidServices_ConditionCheckRead_DidServices_0xf10d_ConditionCheckRead: start-on-event=DidServices_ConditionCheckRead, operation=DidServices_0xf10d.ConditionCheckRead
      OIT_DidServices_ConditionCheckRead_DidServices_0xf154_ConditionCheckRead: start-on-event=DidServices_ConditionCheckRead, operation=DidServices_0xf154.ConditionCheckRead
      OIT_DidServices_ConditionCheckRead_DidServices_0xf155_ConditionCheckRead: start-on-event=DidServices_ConditionCheckRead, operation=DidServices_0xf155.ConditionCheckRead
      OIT_DidServices_ConditionCheckRead_DidServices_0xf158_ConditionCheckRead: start-on-event=DidServices_ConditionCheckRead, operation=DidServices_0xf158.ConditionCheckRead
      OIT_DidServices_ConditionCheckRead_DidServices_0xf{180..188}_ConditionCheckRead: start-on-event=DidServices_ConditionCheckRead, operation=DidServices_0xf{180..188}.ConditionCheckRead
      OIT_DidServices_ConditionCheckRead_DidServices_0xf18c_ConditionCheckRead: start-on-event=DidServices_ConditionCheckRead, operation=DidServices_0xf18c.ConditionCheckRead
      OIT_DidServices_ConditionCheckRead_DidServices_0xf{191..195}_ConditionCheckRead: start-on-event=DidServices_ConditionCheckRead, operation=DidServices_0xf{191..195}.ConditionCheckRead
      OIT_DidServices_ConditionCheckRead_DidServices_0xf1a0_ConditionCheckRead: start-on-event=DidServices_ConditionCheckRead, operation=DidServices_0xf1a0.ConditionCheckRead
      OIT_DidServices_ConditionCheckRead_DidServices_0xf1a3_ConditionCheckRead: start-on-event=DidServices_ConditionCheckRead, operation=DidServices_0xf1a3.ConditionCheckRead
      OIT_DidServices_ConditionCheckRead_DidServices_0xf1a4_ConditionCheckRead: start-on-event=DidServices_ConditionCheckRead, operation=DidServices_0xf1a4.ConditionCheckRead
      OIT_DidServices_ConditionCheckRead_DidServices_0xfd{01..03}_ConditionCheckRead: start-on-event=DidServices_ConditionCheckRead, operation=DidServices_0xfd{01..03}.ConditionCheckRead
      OIT_DidServices_ConditionCheckRead_DidServices_0xfd07_ConditionCheckRead: start-on-event=DidServices_ConditionCheckRead, operation=DidServices_0xfd07.ConditionCheckRead
      OIT_DidServices_ConditionCheckRead_DidServices_0xfd0e_ConditionCheckRead: start-on-event=DidServices_ConditionCheckRead, operation=DidServices_0xfd0e.ConditionCheckRead
      OIT_DidServices_ConditionCheckRead_DidServices_0xfd10_ConditionCheckRead: start-on-event=DidServices_ConditionCheckRead, operation=DidServices_0xfd10.ConditionCheckRead
      OIT_DidServices_ConditionCheckRead_DidServices_0xfd{12..14}_ConditionCheckRead: start-on-event=DidServices_ConditionCheckRead, operation=DidServices_0xfd{12..14}.ConditionCheckRead
      OIT_DidServices_ConditionCheckRead_DidServices_0xfd17_ConditionCheckRead: start-on-event=DidServices_ConditionCheckRead, operation=DidServices_0xfd17.ConditionCheckRead
      OIT_DidServices_ConditionCheckRead_DidServices_0xfd19_ConditionCheckRead: start-on-event=DidServices_ConditionCheckRead, operation=DidServices_0xfd19.ConditionCheckRead
      OIT_DidServices_ConditionCheckRead_DidServices_0xfd1a_ConditionCheckRead: start-on-event=DidServices_ConditionCheckRead, operation=DidServices_0xfd1a.ConditionCheckRead
      OIT_DidServices_ConditionCheckRead_DidServices_0xfd1b_ConditionCheckRead: start-on-event=DidServices_ConditionCheckRead, operation=DidServices_0xfd1b.ConditionCheckRead
      OIT_DidServices_ConditionCheckRead_DidServices_0xfd1c_ConditionCheckRead: start-on-event=DidServices_ConditionCheckRead, operation=DidServices_0xfd1c.ConditionCheckRead
      OIT_DidServices_ConditionCheckRead_DidServices_0xfd1e_ConditionCheckRead: start-on-event=DidServices_ConditionCheckRead, operation=DidServices_0xfd1e.ConditionCheckRead
      OIT_DidServices_ConditionCheckRead_DidServices_0xfd20_ConditionCheckRead: start-on-event=DidServices_ConditionCheckRead, operation=DidServices_0xfd20.ConditionCheckRead
      OIT_DidServices_ConditionCheckRead_DidServices_0xfd21_ConditionCheckRead: start-on-event=DidServices_ConditionCheckRead, operation=DidServices_0xfd21.ConditionCheckRead
      OIT_DidServices_ConditionCheckRead_DidServices_0xfd23_ConditionCheckRead: start-on-event=DidServices_ConditionCheckRead, operation=DidServices_0xfd23.ConditionCheckRead
      OIT_DidServices_ConditionCheckRead_DidServices_0xfd{25..27}_ConditionCheckRead: start-on-event=DidServices_ConditionCheckRead, operation=DidServices_0xfd{25..27}.ConditionCheckRead
      OIT_DidServices_ConditionCheckRead_DidServices_0xfd{29..31}_ConditionCheckRead: start-on-event=DidServices_ConditionCheckRead, operation=DidServices_0xfd{29..31}.ConditionCheckRead
      OIT_DidServices_ConditionCheckRead_DidServices_0xfda{1..3}_ConditionCheckRead: start-on-event=DidServices_ConditionCheckRead, operation=DidServices_0xfda{1..3}.ConditionCheckRead
      OIT_DidServices_ConditionCheckRead_DidServices_0xfdac_ConditionCheckRead: start-on-event=DidServices_ConditionCheckRead, operation=DidServices_0xfdac.ConditionCheckRead
      OIT_DidServices_ConditionCheckRead_DidServices_0xfdad_ConditionCheckRead: start-on-event=DidServices_ConditionCheckRead, operation=DidServices_0xfdad.ConditionCheckRead
      OIT_DidServices_ConditionCheckRead_DidServices_0xfdae_ConditionCheckRead: start-on-event=DidServices_ConditionCheckRead, operation=DidServices_0xfdae.ConditionCheckRead
      OIT_DidServices_ConditionCheckRead_DidServices_0xfdaf_ConditionCheckRead: start-on-event=DidServices_ConditionCheckRead, operation=DidServices_0xfdaf.ConditionCheckRead
      OIT_DidServices_ConditionCheckRead_DidServices_0xfdb{0..7}_ConditionCheckRead: start-on-event=DidServices_ConditionCheckRead, operation=DidServices_0xfdb{0..7}.ConditionCheckRead
      OIT_DidServices_ConditionCheckWrite_DidServices_0x0100_ConditionCheckWrite: start-on-event=DidServices_ConditionCheckWrite, operation=DidServices_0x0100.ConditionCheckWrite
      OIT_DidServices_ConditionCheckWrite_DidServices_0x2023_ConditionCheckWrite: start-on-event=DidServices_ConditionCheckWrite, operation=DidServices_0x2023.ConditionCheckWrite
      OIT_DidServices_ConditionCheckWrite_DidServices_0xf{183..185}_ConditionCheckWrite: start-on-event=DidServices_ConditionCheckWrite, operation=DidServices_0xf{183..185}.ConditionCheckWrite
      OIT_DidServices_ConditionCheckWrite_DidServices_0xf187_ConditionCheckWrite: start-on-event=DidServices_ConditionCheckWrite, operation=DidServices_0xf187.ConditionCheckWrite
      OIT_DidServices_ConditionCheckWrite_DidServices_0xf18c_ConditionCheckWrite: start-on-event=DidServices_ConditionCheckWrite, operation=DidServices_0xf18c.ConditionCheckWrite
      OIT_DidServices_ConditionCheckWrite_DidServices_0xfd02_ConditionCheckWrite: start-on-event=DidServices_ConditionCheckWrite, operation=DidServices_0xfd02.ConditionCheckWrite
      OIT_DidServices_ConditionCheckWrite_DidServices_0xfd03_ConditionCheckWrite: start-on-event=DidServices_ConditionCheckWrite, operation=DidServices_0xfd03.ConditionCheckWrite
      OIT_DidServices_ConditionCheckWrite_DidServices_0xfd07_ConditionCheckWrite: start-on-event=DidServices_ConditionCheckWrite, operation=DidServices_0xfd07.ConditionCheckWrite
      OIT_DidServices_ConditionCheckWrite_DidServices_0xfd12_ConditionCheckWrite: start-on-event=DidServices_ConditionCheckWrite, operation=DidServices_0xfd12.ConditionCheckWrite
      OIT_DidServices_ConditionCheckWrite_DidServices_0xfd19_ConditionCheckWrite: start-on-event=DidServices_ConditionCheckWrite, operation=DidServices_0xfd19.ConditionCheckWrite
      OIT_DidServices_ConditionCheckWrite_DidServices_0xfd1b_ConditionCheckWrite: start-on-event=DidServices_ConditionCheckWrite, operation=DidServices_0xfd1b.ConditionCheckWrite
      OIT_DidServices_ConditionCheckWrite_DidServices_0xfd1e_ConditionCheckWrite: start-on-event=DidServices_ConditionCheckWrite, operation=DidServices_0xfd1e.ConditionCheckWrite
      OIT_DidServices_ConditionCheckWrite_DidServices_0xfd21_ConditionCheckWrite: start-on-event=DidServices_ConditionCheckWrite, operation=DidServices_0xfd21.ConditionCheckWrite
      OIT_DidServices_ConditionCheckWrite_DidServices_0xfd23_ConditionCheckWrite: start-on-event=DidServices_ConditionCheckWrite, operation=DidServices_0xfd23.ConditionCheckWrite
      OIT_DidServices_ConditionCheckWrite_DidServices_0xfd{25..27}_ConditionCheckWrite: start-on-event=DidServices_ConditionCheckWrite, operation=DidServices_0xfd{25..27}.ConditionCheckWrite
      OIT_DidServices_ConditionCheckWrite_DidServices_0xfd29_ConditionCheckWrite: start-on-event=DidServices_ConditionCheckWrite, operation=DidServices_0xfd29.ConditionCheckWrite
      OIT_DidServices_ConditionCheckWrite_DidServices_0xfd30_ConditionCheckWrite: start-on-event=DidServices_ConditionCheckWrite, operation=DidServices_0xfd30.ConditionCheckWrite
      OIT_DidServices_ConditionCheckWrite_DidServices_0xfda{1..3}_ConditionCheckWrite: start-on-event=DidServices_ConditionCheckWrite, operation=DidServices_0xfda{1..3}.ConditionCheckWrite
      OIT_DidServices_ConditionCheckWrite_DidServices_0xfdac_ConditionCheckWrite: start-on-event=DidServices_ConditionCheckWrite, operation=DidServices_0xfdac.ConditionCheckWrite
      OIT_DidServices_ConditionCheckWrite_DidServices_0xfdae_ConditionCheckWrite: start-on-event=DidServices_ConditionCheckWrite, operation=DidServices_0xfdae.ConditionCheckWrite
      OIT_DidServices_ConditionCheckWrite_DidServices_0xfdb{0..7}_ConditionCheckWrite: start-on-event=DidServices_ConditionCheckWrite, operation=DidServices_0xfdb{0..7}.ConditionCheckWrite
      OIT_ResetService_EcuReset_ResetService_EcuReset: start-on-event=ResetService_EcuReset, operation=ResetService.EcuReset
      OIT_RoutineServices_0x0200_RequestResults_RoutineServices_0x0200_RequestResults: start-on-event=RoutineServices_0x0200_RequestResults, operation=RoutineServices_0x0200.RequestResults
      OIT_RoutineServices_0x0200_Start_RoutineServices_0x0200_Start: start-on-event=RoutineServices_0x0200_Start, operation=RoutineServices_0x0200.Start
      OIT_RoutineServices_0xd001_Start_RoutineServices_0xd001_Start: start-on-event=RoutineServices_0xd001_Start, operation=RoutineServices_0xd001.Start
      OIT_RoutineServices_0xd001_Stop_RoutineServices_0xd001_Stop: start-on-event=RoutineServices_0xd001_Stop, operation=RoutineServices_0xd001.Stop
      OIT_RoutineServices_0xd002_Start_RoutineServices_0xd002_Start: start-on-event=RoutineServices_0xd002_Start, operation=RoutineServices_0xd002.Start
      OIT_RoutineServices_0xf000_Start_RoutineServices_0xf000_Start: start-on-event=RoutineServices_0xf000_Start, operation=RoutineServices_0xf000.Start
      OIT_RoutineServices_0xf001_Start_RoutineServices_0xf001_Start: start-on-event=RoutineServices_0xf001_Start, operation=RoutineServices_0xf001.Start
      OIT_RoutineServices_0xf{003..005}_Start_RoutineServices_0xf{003..005}_Start: start-on-event=RoutineServices_0xf{003..005}_Start, operation=RoutineServices_0xf{003..005}.Start
      OIT_RoutineServices_0xf008_Start_RoutineServices_0xf008_Start: start-on-event=RoutineServices_0xf008_Start, operation=RoutineServices_0xf008.Start
      OIT_RoutineServices_0xf009_RequestResults_RoutineServices_0xf009_RequestResults: start-on-event=RoutineServices_0xf009_RequestResults, operation=RoutineServices_0xf009.RequestResults
      OIT_RoutineServices_0xf009_Start_RoutineServices_0xf009_Start: start-on-event=RoutineServices_0xf009_Start, operation=RoutineServices_0xf009.Start
      OIT_RoutineServices_0xf009_Stop_RoutineServices_0xf009_Stop: start-on-event=RoutineServices_0xf009_Stop, operation=RoutineServices_0xf009.Stop
      OIT_RoutineServices_0xf0ff_Start_RoutineServices_0xf0ff_Start: start-on-event=RoutineServices_0xf0ff_Start, operation=RoutineServices_0xf0ff.Start
      OIT_RoutineServices_0xfee0_Start_RoutineServices_0xfee0_Start: start-on-event=RoutineServices_0xfee0_Start, operation=RoutineServices_0xfee0.Start
      OIT_SecurityAccess_1_CompareKey_SecurityAccess_1_CompareKey: start-on-event=SecurityAccess_1_CompareKey, operation=SecurityAccess_1.CompareKey
      OIT_SecurityAccess_1_GetSeed_SecurityAccess_1_GetSeed: start-on-event=SecurityAccess_1_GetSeed, operation=SecurityAccess_1.GetSeed
      OIT_SessionControl_ChangeIndication_SessionControl_ChangeIndication: start-on-event=SessionControl_ChangeIndication, operation=SessionControl.ChangeIndication
      OIT_SessionControl_ConfirmationRespPending_SessionControl_ConfirmationRespPending: start-on-event=SessionControl_ConfirmationRespPending, operation=SessionControl.ConfirmationRespPending
      OIT_SessionControl_GetSesChgPermission_SessionControl_GetSesChgPermission: start-on-event=SessionControl_GetSesChgPermission, operation=SessionControl.GetSesChgPermission
    19 x per instance memory:
      AppSwFingerPrintData: type=Dcm_14Byte_Type, type-definition=/DataType/Dcm_14Byte_Type
      BootSwFingerPrintData: type=Dcm_14Byte_Type, type-definition=/DataType/Dcm_14Byte_Type
      CalSwFingerPrintData: type=Dcm_14Byte_Type, type-definition=/DataType/Dcm_14Byte_Type
      ECULifeTimeMinsData: type=UInt32, type-definition=/DataType/UInt32
      ECUSerialNumberData: type=Dcm_16Byte_Type, type-definition=/DataType/Dcm_16Byte_Type
      ECUSparePartNoData: type=Dcm_11Byte_Type, type-definition=/DataType/Dcm_11Byte_Type
      EOLConfigurationData: type=Dcm_9Byte_Type, type-definition=/DataType/Dcm_9Byte_Type
      EraseRoutineStatusData: type=Dcm_1Byte_Type, type-definition=/DataType/Dcm_1Byte_Type
      FirstDTCDetectMinsData: type=UInt32, type-definition=/DataType/UInt32
      FirstDTCDetectSecsData: type=UInt16, type-definition=/DataType/UInt16
      OdometerFlashProgData: type=UInt16, type-definition=/DataType/UInt16
      ProgrammingAttemptCounterData: type=Dcm_8Byte_Type, type-definition=/DataType/Dcm_8Byte_Type
      ProgrammingStatusData: type=Dcm_1Byte_Type, type-definition=/DataType/Dcm_1Byte_Type
      ProxiConfigurationData: type=Dcm_255Byte_Type, type-definition=/DataType/Dcm_255Byte_Type
      ProxiCounterData: type=Dcm_1Byte_Type, type-definition=/DataType/Dcm_1Byte_Type
      TotalOdometerData: type=UInt16, type-definition=/DataType/UInt16
      TuningSetSelectData: type=UInt16, type-definition=/DataType/UInt16
      VINCurrentData: type=Dcm_17Byte_Type, type-definition=/DataType/Dcm_17Byte_Type
      VINOriginalData: type=Dcm_17Byte_Type, type-definition=/DataType/Dcm_17Byte_Type
    port-api-options:
      enable-take-address=false, indirect-api=false, port=AbsHwPos_SCom
      enable-take-address=false, indirect-api=false, port=AppSwFingerPrint
      enable-take-address=false, indirect-api=false, port=BootSwFingerPrint
      enable-take-address=false, indirect-api=false, port=CalSwFingerPrint
      enable-take-address=false, indirect-api=false, port=CityModeSts
      enable-take-address=false, indirect-api=false, port=CityUserEnableDisable
      enable-take-address=false, indirect-api=false, port=CmdIgnFailSts
      enable-take-address=false, indirect-api=false, port=CmdIgnSts
      enable-take-address=false, indirect-api=false, port=ComControlService
      enable-take-address=false, indirect-api=false, port=DCMServices
      enable-take-address=false, indirect-api=false, port=DesiredTunSet
      enable-take-address=false, indirect-api=false, port=DiagSvc_SCom
      enable-take-address=false, indirect-api=false, port=DidServices_0x0100
      enable-take-address=false, indirect-api=false, port=DidServices_0x0885
      enable-take-address=false, indirect-api=false, port=DidServices_0x0ad9
      enable-take-address=false, indirect-api=false, port=DidServices_0x0ada
      enable-take-address=false, indirect-api=false, port=DidServices_0x0adb
      enable-take-address=false, indirect-api=false, port=DidServices_0x0adc
      enable-take-address=false, indirect-api=false, port=DidServices_0x0ade
      enable-take-address=false, indirect-api=false, port=DidServices_0x1002
      enable-take-address=false, indirect-api=false, port=DidServices_0x1004
      enable-take-address=false, indirect-api=false, port=DidServices_0x1006
      enable-take-address=false, indirect-api=false, port=DidServices_0x1008
      enable-take-address=false, indirect-api=false, port=DidServices_0x1009
      enable-take-address=false, indirect-api=false, port=DidServices_0x102a
      enable-take-address=false, indirect-api=false, port=DidServices_0x191d
      enable-take-address=false, indirect-api=false, port=DidServices_0x1921
      enable-take-address=false, indirect-api=false, port=DidServices_0x{2001..2003}
      enable-take-address=false, indirect-api=false, port=DidServices_0x2008
      enable-take-address=false, indirect-api=false, port=DidServices_0x200a
      enable-take-address=false, indirect-api=false, port=DidServices_0x200b
      enable-take-address=false, indirect-api=false, port=DidServices_0x200c
      enable-take-address=false, indirect-api=false, port=DidServices_0x2010
      enable-take-address=false, indirect-api=false, port=DidServices_0x2014
      enable-take-address=false, indirect-api=false, port=DidServices_0x2023
      enable-take-address=false, indirect-api=false, port=DidServices_0x2024
      enable-take-address=false, indirect-api=false, port=DidServices_0x292e
      enable-take-address=false, indirect-api=false, port=DidServices_0x5051
      enable-take-address=false, indirect-api=false, port=DidServices_0x5052
      enable-take-address=false, indirect-api=false, port=DidServices_0x5aab
      enable-take-address=false, indirect-api=false, port=DidServices_0xf100
      enable-take-address=false, indirect-api=false, port=DidServices_0xf10b
      enable-take-address=false, indirect-api=false, port=DidServices_0xf10d
      enable-take-address=false, indirect-api=false, port=DidServices_0xf154
      enable-take-address=false, indirect-api=false, port=DidServices_0xf155
      enable-take-address=false, indirect-api=false, port=DidServices_0xf158
      enable-take-address=false, indirect-api=false, port=DidServices_0xf{180..188}
      enable-take-address=false, indirect-api=false, port=DidServices_0xf18c
      enable-take-address=false, indirect-api=false, port=DidServices_0xf{191..195}
      enable-take-address=false, indirect-api=false, port=DidServices_0xf1a0
      enable-take-address=false, indirect-api=false, port=DidServices_0xf1a3
      enable-take-address=false, indirect-api=false, port=DidServices_0xf1a4
      enable-take-address=false, indirect-api=false, port=DidServices_0xfd{01..03}
      enable-take-address=false, indirect-api=false, port=DidServices_0xfd07
      enable-take-address=false, indirect-api=false, port=DidServices_0xfd0d
      enable-take-address=false, indirect-api=false, port=DidServices_0xfd0e
      enable-take-address=false, indirect-api=false, port=DidServices_0xfd{10..14}
      enable-take-address=false, indirect-api=false, port=DidServices_0xfd17
      enable-take-address=false, indirect-api=false, port=DidServices_0xfd19
      enable-take-address=false, indirect-api=false, port=DidServices_0xfd1a
      enable-take-address=false, indirect-api=false, port=DidServices_0xfd1b
      enable-take-address=false, indirect-api=false, port=DidServices_0xfd1c
      enable-take-address=false, indirect-api=false, port=DidServices_0xfd1e
      enable-take-address=false, indirect-api=false, port=DidServices_0xfd20
      enable-take-address=false, indirect-api=false, port=DidServices_0xfd21
      enable-take-address=false, indirect-api=false, port=DidServices_0xfd23
      enable-take-address=false, indirect-api=false, port=DidServices_0xfd{25..27}
      enable-take-address=false, indirect-api=false, port=DidServices_0xfd{29..31}
      enable-take-address=false, indirect-api=false, port=DidServices_0xfda{1..3}
      enable-take-address=false, indirect-api=false, port=DidServices_0xfdac
      enable-take-address=false, indirect-api=false, port=DidServices_0xfdad
      enable-take-address=false, indirect-api=false, port=DidServices_0xfdae
      enable-take-address=false, indirect-api=false, port=DidServices_0xfdaf
      enable-take-address=false, indirect-api=false, port=DidServices_0xfdb{0..7}
      enable-take-address=false, indirect-api=false, port=DigColPs_SCom
      enable-take-address=false, indirect-api=false, port=DisableFailSafeReaction
      enable-take-address=false, indirect-api=false, port=ECULifeTimeMins
      enable-take-address=false, indirect-api=false, port=ECUSerialNumberData
      enable-take-address=false, indirect-api=false, port=ECUSparePartNo
      enable-take-address=false, indirect-api=false, port=ElectricStrFailSts
      enable-take-address=false, indirect-api=false, port=EOLConfiguration
      enable-take-address=false, indirect-api=false, port=EraseRoutineStatus
      enable-take-address=false, indirect-api=false, port=FirstDTCDetectMins
      enable-take-address=false, indirect-api=false, port=FirstDTCDetectSecs
      enable-take-address=false, indirect-api=false, port=HwPos
      enable-take-address=false, indirect-api=false, port=HwTrq
      enable-take-address=false, indirect-api=false, port=IgnitionPreStart
      enable-take-address=false, indirect-api=false, port=LrnEOT_Scom
      enable-take-address=false, indirect-api=false, port=MEC
      enable-take-address=false, indirect-api=false, port=NxtrDiagMgr
      enable-take-address=false, indirect-api=false, port=OdometerFlashProg
      enable-take-address=false, indirect-api=false, port=OperationalModeSts
      enable-take-address=false, indirect-api=false, port=PowerLatchTimeDID191D
      enable-take-address=false, indirect-api=false, port=ProgrammingAttemptCounter
      enable-take-address=false, indirect-api=false, port=ProgrammingStatus
      enable-take-address=false, indirect-api=false, port=ProxiConfiguration
      enable-take-address=false, indirect-api=false, port=ProxiCounter
      enable-take-address=false, indirect-api=false, port=ProxiValid
      enable-take-address=false, indirect-api=false, port=ResetService
      enable-take-address=false, indirect-api=false, port=RoutineServices_0x0200
      enable-take-address=false, indirect-api=false, port=RoutineServices_0xd001
      enable-take-address=false, indirect-api=false, port=RoutineServices_0xd002
      enable-take-address=false, indirect-api=false, port=RoutineServices_0xf000
      enable-take-address=false, indirect-api=false, port=RoutineServices_0xf001
      enable-take-address=false, indirect-api=false, port=RoutineServices_0xf{003..005}
      enable-take-address=false, indirect-api=false, port=RoutineServices_0xf008
      enable-take-address=false, indirect-api=false, port=RoutineServices_0xf009
      enable-take-address=false, indirect-api=false, port=RoutineServices_0xf0ff
      enable-take-address=false, indirect-api=false, port=RoutineServices_0xfee0
      enable-take-address=false, indirect-api=false, port=SecurityAccess_1
      enable-take-address=false, indirect-api=false, port=SessionControl
      enable-take-address=false, indirect-api=false, port=StaMd_SCom
      enable-take-address=false, indirect-api=false, port=StartStopLogicEnable
      enable-take-address=false, indirect-api=false, port=SystemState
      enable-take-address=false, indirect-api=false, port=SystemTime
      enable-take-address=false, indirect-api=false, port=Temperature_DegC_f32
      enable-take-address=false, indirect-api=false, port=TotalOdometer
      enable-take-address=false, indirect-api=false, port=TotalOdometerIPC
      enable-take-address=false, indirect-api=false, port=TuningSetSelect
      enable-take-address=false, indirect-api=false, port=Vecu_Volt_f32
      enable-take-address=false, indirect-api=false, port=VehDyn_SCom
      enable-take-address=false, indirect-api=false, port=VehicleSpeedValid
      enable-take-address=false, indirect-api=false, port=VehSpd
      enable-take-address=false, indirect-api=false, port=VINCurrent
      enable-take-address=false, indirect-api=false, port=VINOriginal
    166 x runnable:
      ComControlService_CheckCondition
      DiagSvc_Init1
        data read access READ_MEC_Cnt_enum: data-element=MEC.Cnt_enum
        4 x data write access:
          WRITE_DesiredTunSet_Cnt_u16: data-element=DesiredTunSet.Cnt_u16
          WRITE_IgnitionPreStart_Cnt_lgc: data-element=IgnitionPreStart.Cnt_lgc
          WRITE_ProxiValid_Cnt_lgc: data-element=ProxiValid.Cnt_lgc
          WRITE_StartStopLogicEnable_Cnt_lgc: data-element=StartStopLogicEnable.Cnt_lgc
        8 x sync call, all with timeout=0:
          SC_ECULifeTimeMins_GetErrorStatus: operation=ECULifeTimeMins.GetErrorStatus
          SC_ECULifeTimeMins_ReadBlock: operation=ECULifeTimeMins.ReadBlock
          SC_NxtrDiagMgr_GetNTCFailed: operation=NxtrDiagMgr.GetNTCFailed
          SC_NxtrDiagMgr_SetNTCStatus: operation=NxtrDiagMgr.SetNTCStatus
          SC_ProxiConfiguration_GetErrorStatus: operation=ProxiConfiguration.GetErrorStatus
          SC_ProxiConfiguration_ReadBlock: operation=ProxiConfiguration.ReadBlock
          SC_SystemTime_GetSystemTime_mS_u32: operation=SystemTime.GetSystemTime_mS_u32
          SC_TuningSetSelect_GetErrorStatus: operation=TuningSetSelect.GetErrorStatus
      DiagSvc_Per1
        sync call SC_SystemTime_DtrmnElapsedTime_mS_u16: operation=SystemTime.DtrmnElapsedTime_mS_u16, timeout=0
        sync call SC_SystemTime_GetSystemTime_mS_u32: operation=SystemTime.GetSystemTime_mS_u32, timeout=0
      DiagSvc_SCom_GetTuningSet
        sync call SC_TuningSetSelect_GetErrorStatus: operation=TuningSetSelect.GetErrorStatus, timeout=0
      DiagSvc_SCom_SetTuningSet
        data receive point REC_MEC_Cnt_enum: data-element=MEC.Cnt_enum
        sync call SC_NxtrDiagMgr_SetNTCStatus: operation=NxtrDiagMgr.SetNTCStatus, timeout=0
        sync call SC_TuningSetSelect_InvalidateNvBlock: operation=TuningSetSelect.InvalidateNvBlock, timeout=0
        sync call SC_TuningSetSelect_WriteBlock: operation=TuningSetSelect.WriteBlock, timeout=0
      DiagSvc_Trns1
        data receive point REC_TotalOdometerIPC_Cnt_u32: data-element=TotalOdometerIPC.Cnt_u32
        sync call SC_ECULifeTimeMins_WriteBlock: operation=ECULifeTimeMins.WriteBlock, timeout=0
        sync call SC_SystemTime_DtrmnElapsedTime_mS_u32: operation=SystemTime.DtrmnElapsedTime_mS_u32, timeout=0
        sync call SC_TotalOdometer_WriteBlock: operation=TotalOdometer.WriteBlock, timeout=0
      DidServices_0x0100_ReadData
        sync call SC_TuningSetSelect_GetErrorStatus: operation=TuningSetSelect.GetErrorStatus, timeout=0
      DidServices_0x0100_WriteData
        data receive point REC_MEC_Cnt_enum: data-element=MEC.Cnt_enum
        sync call SC_NxtrDiagMgr_SetNTCStatus: operation=NxtrDiagMgr.SetNTCStatus, timeout=0
        sync call SC_TuningSetSelect_InvalidateNvBlock: operation=TuningSetSelect.InvalidateNvBlock, timeout=0
        sync call SC_TuningSetSelect_WriteBlock: operation=TuningSetSelect.WriteBlock, timeout=0
      DidServices_0x0885_ReadData
        data receive point REC_HwPos_HwDeg_f32: data-element=HwPos.HwDeg_f32
      DidServices_0x0ad9_ReadData
      DidServices_0x0ada_ReadData
        data receive point REC_ElectricStrFailSts_Cnt_lgc: data-element=ElectricStrFailSts.Cnt_lgc
      DidServices_0x0adb_ReadData
        data receive point REC_HwTrq_HwNm_f32: data-element=HwTrq.HwNm_f32
      DidServices_0x0adc_ReadData
        data receive point REC_CityModeSts_Cnt_lgc: data-element=CityModeSts.Cnt_lgc
      DidServices_0x0ade_ReadData
        data receive point REC_Temperature_DegC_f32_DegC_f32: data-element=Temperature_DegC_f32.DegC_f32
      DidServices_0x1002_ReadData
        data receive point REC_VehSpd_Kph_f32: data-element=VehSpd.Kph_f32
      DidServices_0x1004_ReadData
        data receive point REC_Vecu_Volt_f32_Volt_f32: data-element=Vecu_Volt_f32.Volt_f32
      DidServices_0x1006_ReadData
        data receive point REC_Vecu_Volt_f32_Volt_f32: data-element=Vecu_Volt_f32.Volt_f32
      DidServices_0x1008_ReadData
        sync call SC_ECULifeTimeMins_GetErrorStatus: operation=ECULifeTimeMins.GetErrorStatus, timeout=0
        sync call SC_ECULifeTimeMins_ReadBlock: operation=ECULifeTimeMins.ReadBlock, timeout=0
        sync call SC_SystemTime_DtrmnElapsedTime_mS_u32: operation=SystemTime.DtrmnElapsedTime_mS_u32, timeout=0
      DidServices_0x1009_ReadData
        sync call SC_SystemTime_DtrmnElapsedTime_mS_u32: operation=SystemTime.DtrmnElapsedTime_mS_u32, timeout=0
      DidServices_0x102a_ReadData
        sync call SC_EOLConfiguration_GetErrorStatus: operation=EOLConfiguration.GetErrorStatus, timeout=0
        sync call SC_EOLConfiguration_ReadBlock: operation=EOLConfiguration.ReadBlock, timeout=0
      DidServices_0x191d_ReadData
        data receive point REC_PowerLatchTimeDID191D_Cnt_u16: data-element=PowerLatchTimeDID191D.Cnt_u16
      DidServices_0x1921_ReadData
        data receive point REC_CmdIgnFailSts_Cnt_u8: data-element=CmdIgnFailSts.Cnt_u8
        data receive point REC_CmdIgnSts_Cnt_u16: data-element=CmdIgnSts.Cnt_u16
        data receive point REC_OperationalModeSts_Cnt_u16: data-element=OperationalModeSts.Cnt_u16
      DidServices_0x2001_ReadData
        data receive point REC_TotalOdometerIPC_Cnt_u32: data-element=TotalOdometerIPC.Cnt_u32
      DidServices_0x2002_ReadData
        sync call SC_OdometerFlashProg_GetErrorStatus: operation=OdometerFlashProg.GetErrorStatus, timeout=0
        sync call SC_OdometerFlashProg_ReadBlock: operation=OdometerFlashProg.ReadBlock, timeout=0
      DidServices_0x2003_ReadData
        sync call SC_ProgrammingAttemptCounter_GetErrorStatus: operation=ProgrammingAttemptCounter.GetErrorStatus, timeout=0
        sync call SC_ProgrammingAttemptCounter_ReadBlock: operation=ProgrammingAttemptCounter.ReadBlock, timeout=0
      DidServices_0x2008_ReadData
      DidServices_0x200a_ReadData
      DidServices_0x200b_ReadData
        sync call SC_FirstDTCDetectMins_GetErrorStatus: operation=FirstDTCDetectMins.GetErrorStatus, timeout=0
        sync call SC_FirstDTCDetectMins_ReadBlock: operation=FirstDTCDetectMins.ReadBlock, timeout=0
        sync call SC_FirstDTCDetectMins_WriteBlock: operation=FirstDTCDetectMins.WriteBlock, timeout=0
      DidServices_0x200c_ReadData
        sync call SC_FirstDTCDetectSecs_GetErrorStatus: operation=FirstDTCDetectSecs.GetErrorStatus, timeout=0
        sync call SC_FirstDTCDetectSecs_ReadBlock: operation=FirstDTCDetectSecs.ReadBlock, timeout=0
        sync call SC_FirstDTCDetectSecs_WriteBlock: operation=FirstDTCDetectSecs.WriteBlock, timeout=0
      DidServices_0x2010_ReadData
        sync call SC_ProgrammingStatus_GetErrorStatus: operation=ProgrammingStatus.GetErrorStatus, timeout=0
        sync call SC_ProgrammingStatus_ReadBlock: operation=ProgrammingStatus.ReadBlock, timeout=0
      DidServices_0x2014_ReadData
        sync call SC_EraseRoutineStatus_GetErrorStatus: operation=EraseRoutineStatus.GetErrorStatus, timeout=0
        sync call SC_EraseRoutineStatus_ReadBlock: operation=EraseRoutineStatus.ReadBlock, timeout=0
      DidServices_0x2023_WriteData
        4 x sync call, all with timeout=0:
          SC_EOLConfiguration_WriteBlock: operation=EOLConfiguration.WriteBlock
          SC_ProxiConfiguration_WriteBlock: operation=ProxiConfiguration.WriteBlock
          SC_ProxiCounter_WriteBlock: operation=ProxiCounter.WriteBlock
          SC_TuningSetSelect_WriteBlock: operation=TuningSetSelect.WriteBlock
      DidServices_0x2024_ReadData
        sync call SC_ProxiConfiguration_GetErrorStatus: operation=ProxiConfiguration.GetErrorStatus, timeout=0
        sync call SC_ProxiConfiguration_ReadBlock: operation=ProxiConfiguration.ReadBlock, timeout=0
      DidServices_0x292e_ReadData
        sync call SC_ProxiCounter_GetErrorStatus: operation=ProxiCounter.GetErrorStatus, timeout=0
        sync call SC_ProxiCounter_ReadBlock: operation=ProxiCounter.ReadBlock, timeout=0
      DidServices_0x5051_ResetToDefault
      DidServices_0x5051_ReturnControlToECU
      DidServices_0x5051_ShortTermAdjustment
      DidServices_0x5052_ReturnControlToECU
        sync call SC_ProxiConfiguration_GetErrorStatus: operation=ProxiConfiguration.GetErrorStatus, timeout=0
        sync call SC_ProxiConfiguration_ReadBlock: operation=ProxiConfiguration.ReadBlock, timeout=0
      DidServices_0x5052_ShortTermAdjustment
      DidServices_0x5aab_ResetToDefault
        data send point SEND_CityUserEnableDisable_Cnt_enum: data-element=CityUserEnableDisable.Cnt_enum
      DidServices_0x5aab_ReturnControlToECU
        data send point SEND_CityUserEnableDisable_Cnt_enum: data-element=CityUserEnableDisable.Cnt_enum
      DidServices_0x5aab_ShortTermAdjustment
        data send point SEND_CityUserEnableDisable_Cnt_enum: data-element=CityUserEnableDisable.Cnt_enum
      DidServices_0xf100_ReadData
      DidServices_0xf10b_ReadData
      DidServices_0xf10b_ReadDataLength
      DidServices_0xf10d_ReadData
      DidServices_0xf154_ReadData
      DidServices_0xf155_ReadData
      DidServices_0xf158_ReadData
      DidServices_0xf{180..182}_ReadData
      DidServices_0xf183_ReadData
        sync call SC_BootSwFingerPrint_GetErrorStatus: operation=BootSwFingerPrint.GetErrorStatus, timeout=0
        sync call SC_BootSwFingerPrint_ReadBlock: operation=BootSwFingerPrint.ReadBlock, timeout=0
      DidServices_0xf183_WriteData
      DidServices_0xf184_ReadData
        sync call SC_AppSwFingerPrint_GetErrorStatus: operation=AppSwFingerPrint.GetErrorStatus, timeout=0
        sync call SC_AppSwFingerPrint_ReadBlock: operation=AppSwFingerPrint.ReadBlock, timeout=0
      DidServices_0xf184_WriteData
      DidServices_0xf185_ReadData
        sync call SC_CalSwFingerPrint_GetErrorStatus: operation=CalSwFingerPrint.GetErrorStatus, timeout=0
        sync call SC_CalSwFingerPrint_ReadBlock: operation=CalSwFingerPrint.ReadBlock, timeout=0
      DidServices_0xf185_WriteData
      DidServices_0xf186_ReadData
      DidServices_0xf187_ReadData
        sync call SC_ECUSparePartNo_GetErrorStatus: operation=ECUSparePartNo.GetErrorStatus, timeout=0
        sync call SC_ECUSparePartNo_ReadBlock: operation=ECUSparePartNo.ReadBlock, timeout=0
      DidServices_0xf187_WriteData
        sync call SC_ECUSparePartNo_SetRamBlockStatus: operation=ECUSparePartNo.SetRamBlockStatus, timeout=0
      DidServices_0xf188_ReadData
      DidServices_0xf18c_ReadData
        sync call SC_ECUSerialNumberData_GetErrorStatus: operation=ECUSerialNumberData.GetErrorStatus, timeout=0
        sync call SC_ECUSerialNumberData_ReadBlock: operation=ECUSerialNumberData.ReadBlock, timeout=0
      DidServices_0xf18c_WriteData
        sync call SC_ECUSerialNumberData_WriteBlock: operation=ECUSerialNumberData.WriteBlock, timeout=0
      DidServices_0xf{191..195}_ReadData
      DidServices_0xf1a0_ReadData
      DidServices_0xf1a3_ReadData
      DidServices_0xf1a4_ReadData
      DidServices_0xfd01_ReadData
      DidServices_0xfd02_ReadData
      DidServices_0xfd02_WriteData
      DidServices_0xfd03_ReadData
      DidServices_0xfd03_WriteData
      DidServices_0xfd07_ReadData
      DidServices_0xfd07_WriteData
      DidServices_0xfd0d_ReturnControlToECU
      DidServices_0xfd0d_ShortTermAdjustment
      DidServices_0xfd0e_ReadData
      DidServices_0xfd10_ReadData
      DidServices_0xfd11_ReturnControlToECU
      DidServices_0xfd11_ShortTermAdjustment
      DidServices_0xfd12_ReadData
      DidServices_0xfd12_WriteData
      DidServices_0xfd13_ReadData
      DidServices_0xfd14_ReadData
      DidServices_0xfd17_ReadData
      DidServices_0xfd19_ReadData
      DidServices_0xfd19_WriteData
      DidServices_0xfd1a_ReadData
      DidServices_0xfd1b_ReadData
      DidServices_0xfd1b_WriteData
      DidServices_0xfd1c_ReadData
      DidServices_0xfd1e_ReadData
      DidServices_0xfd1e_WriteData
      DidServices_0xfd20_ReadData
      DidServices_0xfd21_ReadData
      DidServices_0xfd21_WriteData
      DidServices_0xfd23_ReadData
      DidServices_0xfd23_WriteData
      DidServices_0xfd25_ReadData
      DidServices_0xfd25_WriteData
      DidServices_0xfd26_ReadData
      DidServices_0xfd26_WriteData
      DidServices_0xfd27_ReadData
      DidServices_0xfd27_WriteData
      DidServices_0xfd29_ReadData
      DidServices_0xfd29_WriteData
      DidServices_0xfd30_ReadData
      DidServices_0xfd30_WriteData
      DidServices_0xfd31_ReadData
      DidServices_0xfda1_ReadData
      DidServices_0xfda1_WriteData
      DidServices_0xfda2_ReadData
      DidServices_0xfda2_WriteData
      DidServices_0xfda3_ReadData
      DidServices_0xfda3_WriteData
      DidServices_0xfdac_ReadData
      DidServices_0xfdac_WriteData
      DidServices_0xfdad_ReadData
      DidServices_0xfdae_ReadData
      DidServices_0xfdae_WriteData
      DidServices_0xfdaf_ReadData
      DidServices_0xfdb0_ReadData
      DidServices_0xfdb0_WriteData
      DidServices_0xfdb1_ReadData
      DidServices_0xfdb1_WriteData
      DidServices_0xfdb2_ReadData
      DidServices_0xfdb2_WriteData
      DidServices_0xfdb3_ReadData
      DidServices_0xfdb3_WriteData
      DidServices_0xfdb4_ReadData
      DidServices_0xfdb4_WriteData
      DidServices_0xfdb5_ReadData
      DidServices_0xfdb5_WriteData
      DidServices_0xfdb6_ReadData
      DidServices_0xfdb6_WriteData
      DidServices_0xfdb7_ReadData
      DidServices_0xfdb7_WriteData
      DidServices_ConditionCheckRead
      DidServices_ConditionCheckWrite
      ResetService_EcuReset
      RoutineServices_0x0200_RequestResults
        data receive point REC_HwTrq_HwNm_f32: data-element=HwTrq.HwNm_f32
        data receive point REC_VehSpd_Kph_f32: data-element=VehSpd.Kph_f32
        sync call SC_NxtrDiagMgr_GetNTCFailed: operation=NxtrDiagMgr.GetNTCFailed, timeout=0
      RoutineServices_0x0200_Start
        data receive point REC_HwTrq_HwNm_f32: data-element=HwTrq.HwNm_f32
        data receive point REC_VehicleSpeedValid_Cnt_lgc: data-element=VehicleSpeedValid.Cnt_lgc
        data receive point REC_VehSpd_Kph_f32: data-element=VehSpd.Kph_f32
        sync call SC_DigColPs_SCom_CustClearTrim: operation=DigColPs_SCom.CustClearTrim, timeout=0
        sync call SC_DigColPs_SCom_CustSetTrim: operation=DigColPs_SCom.CustSetTrim, timeout=0
      RoutineServices_0xd001_Start
        data send point SEND_DisableFailSafeReaction_Cnt_lgc: data-element=DisableFailSafeReaction.Cnt_lgc
      RoutineServices_0xd001_Stop
        data send point SEND_DisableFailSafeReaction_Cnt_lgc: data-element=DisableFailSafeReaction.Cnt_lgc
      RoutineServices_0xd002_Start
        4 x data receive point:
          REC_HwTrq_HwNm_f32: data-element=HwTrq.HwNm_f32
          REC_Temperature_DegC_f32_DegC_f32: data-element=Temperature_DegC_f32.DegC_f32
          REC_Vecu_Volt_f32_Volt_f32: data-element=Vecu_Volt_f32.Volt_f32
          REC_VehSpd_Kph_f32: data-element=VehSpd.Kph_f32
      RoutineServices_0xf000_Start
      RoutineServices_0xf001_Start
      RoutineServices_0xf{003..005}_Start
      RoutineServices_0xf008_Start
      RoutineServices_0xf009_RequestResults
      RoutineServices_0xf009_Start
      RoutineServices_0xf009_Stop
      RoutineServices_0xf0ff_Start
      RoutineServices_0xfee0_Start
        4 x sync call, all with timeout=0:
          SC_AbsHwPos_SCom_CustClrTrim: operation=AbsHwPos_SCom.CustClrTrim
          SC_AbsHwPos_SCom_CustSetTrim: operation=AbsHwPos_SCom.CustSetTrim
          SC_LrnEOT_Scom_ResetEOT: operation=LrnEOT_Scom.ResetEOT
          SC_VehDyn_SCom_ResetCenter: operation=VehDyn_SCom.ResetCenter
      SecurityAccess_1_CompareKey
      SecurityAccess_1_GetSeed
        sync call SC_DCMServices_GetSecurityLevel: operation=DCMServices.GetSecurityLevel, timeout=0
      SessionControl_ChangeIndication
        data receive point REC_TotalOdometerIPC_Cnt_u32: data-element=TotalOdometerIPC.Cnt_u32
        sync call SC_ECULifeTimeMins_WriteBlock: operation=ECULifeTimeMins.WriteBlock, timeout=0
        sync call SC_SystemTime_DtrmnElapsedTime_mS_u32: operation=SystemTime.DtrmnElapsedTime_mS_u32, timeout=0
        sync call SC_TotalOdometer_WriteBlock: operation=TotalOdometer.WriteBlock, timeout=0
      SessionControl_ConfirmationRespPending
        data receive point REC_TotalOdometerIPC_Cnt_u32: data-element=TotalOdometerIPC.Cnt_u32
        sync call SC_ECULifeTimeMins_WriteBlock: operation=ECULifeTimeMins.WriteBlock, timeout=0
        sync call SC_SystemTime_DtrmnElapsedTime_mS_u32: operation=SystemTime.DtrmnElapsedTime_mS_u32, timeout=0
        sync call SC_TotalOdometer_WriteBlock: operation=TotalOdometer.WriteBlock, timeout=0
      SessionControl_GetSesChgPermission
    service-needss:
      19 x swc nv block needs, all with n-data-sets=0, readonly=false, reliability=LOW, resistant-to-changed-sw=false, restore-at-start=false, write-only-once=false, writing-frequency=0, writing-priority=LOW:
        VINOriginal: mirror-block=VINOriginalData
        VINCurrent: mirror-block=VINCurrentData
        TuningSetSelect: mirror-block=TuningSetSelectData
        TotalOdometer: mirror-block=TotalOdometerData
        ProxiCounter: mirror-block=ProxiCounterData
        ProxiConfiguration: mirror-block=ProxiConfigurationData
        ProgrammingStatus: mirror-block=ProgrammingStatusData
        ProgrammingAttemptCounter: mirror-block=ProgrammingAttemptCounterData
        OdometerFlashProg: mirror-block=OdometerFlashProgData
        FirstDTCDetectSecs: mirror-block=FirstDTCDetectSecsData
        FirstDTCDetectMins: mirror-block=FirstDTCDetectMinsData
        EraseRoutineStatus: mirror-block=EraseRoutineStatusData
        EOLConfiguration: mirror-block=EOLConfigurationData
        ECUSparePartNo: mirror-block=ECUSparePartNoData
        ECUSerialNumber: mirror-block=ECUSerialNumberData
        ECULifeTimeMins: mirror-block=ECULifeTimeMinsData
        CalSwFingerPrint: mirror-block=CalSwFingerPrintData
        BootSwFingerPrint: mirror-block=BootSwFingerPrintData
        AppSwFingerPrint: mirror-block=AppSwFingerPrintData
  swc implementation Ap_DiagSvc_Implementation: behavior=Ap_DiagSvc_InternalBehavior
    code-descriptors:
      code Code: type=SRC
